VERSION ""

NS_ :

BS_:

BU_: Turbocharger OnBoardDataLogger OffBoardDiagnosticTool2 OffBoardDiagnosticTool1 FileServer ParkingBrakeController SeatControl2 FanDriveController SteeringColumnUnit CommunicationUnitRadio CommunicationUnitSatellite CommunicationUnitCellular PropulsionBatteryCharger ChassisController2 ChassisController1 EngineValveControl AuxiliaryHeater2 AuxiliaryHeater1 ClutchUnit RampControl InformationSystem1 SuspensionSystemController2 OilSensor VehicleDynamicStability ExhaustEmissionController TransmissionDisplay2 TransmissionDisplay1 ClimateControl2 WaterPumpController RearAxleSteeringController LightingOperatorControl SeatController1 IgnitionController2 IgnitionController1 TirePressureController CabController2 CabController1 PneumaticSystemController SuspensionSystemController1 HydraulicPumpController EnduranceBrakingSystem RetarderExhaustEngine2 OnBoardDiagnosticUnit HeadwayController RetarderExhaustEngine1 CabDisplay1 ManagementComputer VirtualTerminal OffVehicleGateway PowerTakeOffFront HitchControl AuxiliaryValveControl BodyController TractorTrailerBridge1 StarterSystem ElectricalSystem VehicleSecurity VehicleNavigation AerodynamicControl ElectricalChargingSystem ClimateControl1 TripRecorder InstrumentCluster SuspensionDriveAxle2 SuspensionDriveAxle1 SuspensionSteerAxle SteeringController FuelSystem CruiseControl RetarderDriveline RetarderEngine BrakesDriveAxle2 BrakesDriveAxle1 BrakesSystemController BrakesSteerAxle AxleDrive2 AxleDrive1 AxleSteering PowerTakeOff ShiftConsoleSecondary ShiftConsolePrimary Transmission2 Transmission1 Engine2 Engine1

BO_ 2632384254 VT12: 34 Vector__XXX
 SG_ VTFunctionVTtoECU M : 0|8@1+ (1,0) [0|255] "" Vector__XXX
 SG_ NumberOfAuxiliaryUnits m39 : 8|8@1+ (1,0) [0|255] "" Vector__XXX
 SG_ BootTime m199 : 8|8@1+ (1,0) [0|255] "s" Vector__XXX
 SG_ NumberOfSupportedObjects m197 : 8|8@1+ (1,0) [0|255] "" Vector__XXX
 SG_ BckgndColourUserLayoutDataMask m196 : 8|8@1+ (1,0) [0|255] "" Vector__XXX
 SG_ ObjectID_1 m9 : 8|16@1+ (1,0) [0|65535] "" Vector__XXX
 SG_ InputNumber m33 : 8|8@1+ (1,0) [0|250] "" Vector__XXX
 SG_ TerminationCause m10 : 8|8@1+ (1,0) [0|255] "" Vector__XXX
 SG_ KeyActivationCode m0 : 8|8@1+ (1,0) [0|2] "" Vector__XXX
 SG_ ButtonActivationCode m1 : 8|8@1+ (1,0) [0|2] "" Vector__XXX
 SG_ XPosition m2 : 8|16@1+ (1,0) [0|65535] "" Vector__XXX
 SG_ VTSelectInputObjectID m3 : 8|16@1+ (1,0) [0|65535] "" Vector__XXX
 SG_ VTEscObjectID m4 : 8|16@1+ (1,0) [0|65535] "" Vector__XXX
 SG_ VTChangeNumericValueObjectID m5 : 8|16@1+ (1,0) [0|65535] "" Vector__XXX
 SG_ VTChangeActiveMaskObjectID m6 : 8|16@1+ (1,0) [0|65535] "" Vector__XXX
 SG_ VTChangeSoftKeyMaskParentID m7 : 8|16@1+ (1,0) [0|65535] "" Vector__XXX
 SG_ ObjectToChangeStringID m8 : 8|16@1+ (1,0) [0|65535] "" Vector__XXX
 SG_ ErrorCodeEndOfObjectPool1 m18 : 8|1@1+ (1,0) [0|1] "" Vector__XXX
 SG_ IdentityNumber m36 : 8|21@1+ (1,0) [0|2097152] "" Vector__XXX
 SG_ InputObjectId m38 : 8|16@1+ (1,0) [0|255] "" Vector__XXX
 SG_ AuxPreferredAssignmentRespError1 m34 : 8|1@1+ (1,0) [0|1] "" Vector__XXX
 SG_ InputStatusObjectId m37 : 8|16@1+ (1,0) [0|255] "" Vector__XXX
 SG_ ObjectEscapeID m146 : 8|16@1+ (1,0) [0|65535] "" Vector__XXX
 SG_ ObjectToHideShowID m160 : 8|16@1+ (1,0) [0|65535] "" Vector__XXX
 SG_ ObjectToEnableDisableID m161 : 8|16@1+ (1,0) [0|65535] "" Vector__XXX
 SG_ SelectInputObjectID m162 : 8|16@1+ (1,0) [0|65535] "" Vector__XXX
 SG_ ErrorCodeControlAudioDevice1 m163 : 8|1@1+ (1,0) [0|1] "" Vector__XXX
 SG_ ErrorCodeAudioVolume1 m164 : 8|1@1+ (1,0) [0|1] "" Vector__XXX
 SG_ ChangeChildLocationParentOb_0001 m165 : 8|16@1+ (1,0) [0|65535] "" Vector__XXX
 SG_ ObjectToSizeID m166 : 8|16@1+ (1,0) [0|65535] "" Vector__XXX
 SG_ ObjectToChangeColourID m167 : 8|16@1+ (1,0) [0|65535] "" Vector__XXX
 SG_ ObjectToChangeNumValueID m168 : 8|16@1+ (1,0) [0|65535] "" Vector__XXX
 SG_ ObjectToChangeEndPointID m169 : 8|16@1+ (1,0) [0|65535] "" Vector__XXX
 SG_ ObjectToChangeFontID m170 : 8|16@1+ (1,0) [0|65535] "" Vector__XXX
 SG_ ObjectToChangeLineAttributeID m171 : 8|16@1+ (1,0) [0|65535] "" Vector__XXX
 SG_ ObjectToChangeFillAttributesID m172 : 8|16@1+ (1,0) [0|65535] "" Vector__XXX
 SG_ ActiveMaskObjectID m173 : 8|16@1+ (1,0) [0|0] "" Vector__XXX
 SG_ DataOrAlarmMaskObjectID m174 : 8|16@1+ (1,0) [0|65535] "" Vector__XXX
 SG_ ObjectToChangeAttributeID m175 : 8|16@1+ (1,0) [0|65535] "" Vector__XXX
 SG_ AlarmMaskObjectID m176 : 8|16@1+ (1,0) [0|65535] "" Vector__XXX
 SG_ ListInputObjectID m177 : 8|16@1+ (1,0) [0|65535] "" Vector__XXX
 SG_ ErrorCodeDeleteObjectPool1 m178 : 8|1@1+ (1,0) [0|1] "" Vector__XXX
 SG_ ChangeChildPositionParentOb_0001 m180 : 8|16@1+ (1,0) [0|65535] "" Vector__XXX
 SG_ ErrorCodeSetObjectLabel1 m181 : 8|1@1+ (1,0) [0|1] "" Vector__XXX
 SG_ PolygonObjectToChangeID m182 : 8|16@1+ (1,0) [0|65535] "" Vector__XXX
 SG_ PolygonObjectToScaleID m183 : 8|16@1+ (1,0) [0|65535] "" Vector__XXX
 SG_ GraphicsContextObjectID m184 : 8|16@1+ (1,0) [0|65535] "" Vector__XXX
 SG_ ObjectToGetAttributeID m185 : 8|16@1+ (1,0) [0|65535] "" Vector__XXX
 SG_ ColourMapObjectID m186 : 8|16@1+ (1,0) [0|65535] "" Vector__XXX
 SG_ LockUnlockCommand m189 : 8|8@1+ (1,0) [0|1] "" Vector__XXX
 SG_ MacroObjecID m190 : 8|8@1+ (1,0) [0|255] "" Vector__XXX
 SG_ VersionNumberISO11783Part6 m192 : 8|8@1+ (1,0) [0|255] "" Vector__XXX
 SG_ CodePlane m193 : 8|8@1+ (1,0) [0|16] "" Vector__XXX
 SG_ NavigationSoftKeys m194 : 8|8@1+ (1,0) [0|254] "" Vector__XXX
 SG_ NrOfVersionStrings m224 : 8|8@1+ (1,0) [0|255] "" Vector__XXX
 SG_ ParentIDOfFaultyObject m240 : 8|16@1+ (1,0) [0|65535] "" Vector__XXX
 SG_ SourceAdressOfActiveWSM m254 : 8|8@1+ (1,0) [0|255] "" Vector__XXX
 SG_ ErrorCodeEndOfObjectPool2 m18 : 9|1@1+ (1,0) [0|1] "" Vector__XXX
 SG_ AuxPreferredAssignmentRespError2 m34 : 9|1@1+ (1,0) [0|1] "" Vector__XXX
 SG_ ErrorCodeSetObjectLabel2 m181 : 9|1@1+ (1,0) [0|1] "" Vector__XXX
 SG_ AuxPreferredAssignmentRespError3 m34 : 10|1@1+ (1,0) [0|1] "" Vector__XXX
 SG_ ErrorCodeSetObjectLabel3 m181 : 10|1@1+ (1,0) [0|1] "" Vector__XXX
 SG_ AuxPreferredAssignmentRespError4 m34 : 11|1@1+ (1,0) [0|1] "" Vector__XXX
 SG_ ErrorCodeSetObjectLabel4 m181 : 11|1@1+ (1,0) [0|1] "" Vector__XXX
 SG_ AuxPreferredAssignmentRespError5 m34 : 12|1@1+ (1,0) [0|1] "" Vector__XXX
 SG_ ErrorCodeEndOfObjectPool3 m18 : 12|1@1+ (1,0) [0|1] "" Vector__XXX
 SG_ ErrorCodeControlAudioDevice2 m163 : 12|1@1+ (1,0) [0|1] "" Vector__XXX
 SG_ ErrorCodeAudioVolume2 m164 : 12|1@1+ (1,0) [0|1] "" Vector__XXX
 SG_ ErrorCodeDeleteObjectPool2 m178 : 12|1@1+ (1,0) [0|1] "" Vector__XXX
 SG_ ErrorCodeSetObjectLabel5 m181 : 12|1@1+ (1,0) [0|1] "" Vector__XXX
 SG_ ErrorCodeSetObjectLabel6 m181 : 13|1@1+ (1,0) [0|1] "" Vector__XXX
 SG_ BckgndColourUserLayoutSoftkeyMas m196 : 16|8@1+ (1,0) [0|255] "" Vector__XXX
 SG_ AnalogValue m33 : 16|16@1+ (1,0) [0|65535] "" Vector__XXX
 SG_ AuxFunctObjOfFaultyAssignment m34 : 16|16@1- (1,0) [0|65535] "" Vector__XXX
 SG_ KeyObjectID m0 : 16|16@1+ (1,0) [0|65535] "" Vector__XXX
 SG_ ButtonObjectID m1 : 16|16@1+ (1,0) [0|65535] "" Vector__XXX
 SG_ ParentObjectIDOfFaultyObject m18 : 16|16@1+ (1,0) [0|65535] "" Vector__XXX
 SG_ ErrorCodeLockUnlockMask1 m189 : 16|1@1+ (1,0) [0|1] "" Vector__XXX
 SG_ ErrorCodeExecuteMacro1 m190 : 16|1@1+ (1,0) [0|1] "" Vector__XXX
 SG_ MemoryStatus m192 : 16|8@1+ (1,0) [0|1] "" Vector__XXX
 SG_ FirstWideChar m193 : 16|16@1+ (1,0) [0|65535] "" Vector__XXX
 SG_ SupportedGraphicMode m199 : 16|8@1+ (1,0) [0|2] "" Vector__XXX
 SG_ VersionLables m224 : 16|56@1+ (1,0) [0|0] "" Vector__XXX
 SG_ VisibleDataOrAlarmMaskObjectID m254 : 16|16@1+ (1,0) [0|65535] "" Vector__XXX
 SG_ ExtendedVersionLables m211 : 16|256@1+ (1,0) [0|7.20575940379279E+016] "" Vector__XXX
 SG_ NameOfAuxiliaryUnit1 m39 : 16|64@1+ (1,0) [0|0] "" Vector__XXX
 SG_ ErrorCodeLockUnlockMask2 m189 : 17|1@1+ (1,0) [0|1] "" Vector__XXX
 SG_ ErrorCodeExecuteMacro2 m190 : 17|1@1+ (1,0) [0|1] "" Vector__XXX
 SG_ ErrorCodeLockUnlockMask3 m189 : 18|1@1+ (1,0) [0|1] "" Vector__XXX
 SG_ ErrorCodeExecuteMacro3 m190 : 18|1@1+ (1,0) [0|1] "" Vector__XXX
 SG_ ErrorCodeLockUnlockMask4 m189 : 19|1@1+ (1,0) [0|1] "" Vector__XXX
 SG_ ErrorCodeLockUnlockMask5 m189 : 20|1@1+ (1,0) [0|1] "" Vector__XXX
 SG_ ErrorCodeLockUnlockMask6 m189 : 21|1@1+ (1,0) [0|1] "" Vector__XXX
 SG_ ErrorCodeLockUnlockMask7 m189 : 22|1@1+ (1,0) [0|1] "" Vector__XXX
 SG_ ErrorCodeLockUnlockMask8 m189 : 23|1@1+ (1,0) [0|1] "" Vector__XXX
 SG_ Status_1 m9 : 24|8@1+ (1,0) [0|1] "" Vector__XXX
 SG_ YPosition m2 : 24|16@1+ (1,0) [0|65535] "" Vector__XXX
 SG_ VTSelectInputObjectStatus m3 : 24|8@1+ (1,0) [0|1] "" Vector__XXX
 SG_ ErrorCodeVTEsc1 m4 : 24|1@1+ (1,0) [0|1] "" Vector__XXX
 SG_ VTChangeSoftKeyMaskObjectID m7 : 24|16@1+ (1,0) [0|65535] "" Vector__XXX
 SG_ EnteredStringValue m8 : 24|8@1+ (1,0) [0|255] "" Vector__XXX
 SG_ Value1 m38 : 24|16@1+ (1,0) [0|65535] "" Vector__XXX
 SG_ AuxInputEnable m37 : 24|8@1+ (1,0) [0|1] "" Vector__XXX
 SG_ ErrorCodeEscapeObj1 m146 : 24|1@1+ (1,0) [0|1] "" Vector__XXX
 SG_ ObjectShowStatus m160 : 24|8@1+ (1,0) [0|1] "" Vector__XXX
 SG_ ObjectEnableStatus m161 : 24|8@1+ (1,0) [0|1] "" Vector__XXX
 SG_ ObjectSelectStatus m162 : 24|8@1+ (1,0) [0|2] "" Vector__XXX
 SG_ ChangeChildLocationObjectID m165 : 24|16@1+ (1,0) [0|65535] "" Vector__XXX
 SG_ ErrorCodeObjToSize1 m166 : 24|1@1+ (1,0) [0|1] "" Vector__XXX
 SG_ NewBackgroundColour m167 : 24|8@1+ (1,0) [0|255] "" Vector__XXX
 SG_ ErrorCodeChangeNumValue1 m168 : 24|1@1+ (1,0) [0|1] "" Vector__XXX
 SG_ ErrorCodeChangeEditPoint1 m169 : 24|1@1+ (1,0) [0|1] "" Vector__XXX
 SG_ ErrorCodeChangeFont1 m170 : 24|1@1+ (1,0) [0|1] "" Vector__XXX
 SG_ ErrorCodeChangeLineAttribute1 m171 : 24|1@1+ (1,0) [0|1] "" Vector__XXX
 SG_ ErrorCodeChangeFillAttributes1 m172 : 24|1@1+ (1,0) [0|1] "" Vector__XXX
 SG_ ErrorCodeChangeActiveMask1 m173 : 24|1@1+ (1,0) [0|1] "" Vector__XXX
 SG_ SoftKeyMaskObjectID m174 : 24|16@1+ (1,0) [0|65535] "" Vector__XXX
 SG_ AttributeToChangeID m175 : 24|8@1+ (1,0) [0|65535] "" Vector__XXX
 SG_ NewPriority m176 : 24|8@1+ (1,0) [0|255] "" Vector__XXX
 SG_ ListIndex m177 : 24|8@1+ (1,0) [0|255] "" Vector__XXX
 SG_ ChangeStringValueObjectID m179 : 24|16@1+ (1,0) [0|65535] "" Vector__XXX
 SG_ ChangeChildPositionObjectID m180 : 24|16@1+ (1,0) [0|65535] "" Vector__XXX
 SG_ ErrorCodeChangePoygonPoint1 m182 : 24|1@1+ (1,0) [0|1] "" Vector__XXX
 SG_ NewWidthAttribute m183 : 24|16@1+ (1,0) [0|65535] "" Vector__XXX
 SG_ SubCommandID m184 : 24|8@1+ (1,0) [0|0] "" Vector__XXX
 SG_ AttributeID m185 : 24|8@1+ (1,0) [0|16777200] "" Vector__XXX
 SG_ ErrorCodeSelectColourMap1 m186 : 24|1@1+ (1,0) [0|1] "" Vector__XXX
 SG_ Hardware1 m199 : 24|1@1+ (1,0) [0|1] "" Vector__XXX
 SG_ ObjectIDOfFaultyObject m240 : 24|16@1+ (1,0) [0|65535] "" Vector__XXX
 SG_ ErrorCodeExecuteOpCode1 m11 : 24|1@1+ (1,0) [0|1] "" Vector__XXX
 SG_ ErrorCodeObjToSize2 m166 : 25|1@1+ (1,0) [0|1] "" Vector__XXX
 SG_ ErrorCodeChangeNumValue2 m168 : 25|1@1+ (1,0) [0|1] "" Vector__XXX
 SG_ ErrorCodeChangeEditPoint2 m169 : 25|1@1+ (1,0) [0|1] "" Vector__XXX
 SG_ ErrorCodeChangeFont2 m170 : 25|1@1+ (1,0) [0|1] "" Vector__XXX
 SG_ ErrorCodeChangeLineAttribute2 m171 : 25|1@1+ (1,0) [0|1] "" Vector__XXX
 SG_ ErrorCodeChangeFillAttributes2 m172 : 25|1@1+ (1,0) [0|1] "" Vector__XXX
 SG_ ErrorCodeChangeActiveMask2 m173 : 25|1@1+ (1,0) [0|1] "" Vector__XXX
 SG_ ErrorCodeChangePoygonPoint2 m182 : 25|1@1+ (1,0) [0|1] "" Vector__XXX
 SG_ ErrorCodeSelectColourMap2 m186 : 25|1@1+ (1,0) [0|1] "" Vector__XXX
 SG_ Hardware2 m199 : 25|1@1+ (1,0) [0|1] "" Vector__XXX
 SG_ ErrorCodeExecuteOpCode2 m11 : 25|1@1+ (1,0) [0|1] "" Vector__XXX
 SG_ ErrorCodeMissingObjects m6 : 26|1@1+ (1,0) [0|1] "" Vector__XXX
 SG_ ErrorCodeObjToSize3 m166 : 26|1@1+ (1,0) [0|1] "" Vector__XXX
 SG_ ErrorCodeChangeFont3 m170 : 26|1@1+ (1,0) [0|1] "" Vector__XXX
 SG_ ErrorCodeChangeLineAttribute3 m171 : 26|1@1+ (1,0) [0|1] "" Vector__XXX
 SG_ ErrorCodeChangeFillAttributes3 m172 : 26|1@1+ (1,0) [0|1] "" Vector__XXX
 SG_ ErrorCodeChangeActiveMask3 m173 : 26|1@1+ (1,0) [0|1] "" Vector__XXX
 SG_ ErrorCodeChangePoygonPoint3 m182 : 26|1@1+ (1,0) [0|1] "" Vector__XXX
 SG_ Hardware3 m199 : 26|1@1+ (1,0) [0|1] "" Vector__XXX
 SG_ ErrorCodeExecuteOpCode3 m11 : 26|1@1+ (1,0) [0|1] "" Vector__XXX
 SG_ ErrorCodeChangeNumValue3 m168 : 26|1@1+ (1,0) [0|1] "" Vector__XXX
 SG_ ErrorCodeMaskOrChildObjectError m6 : 27|1@1+ (1,0) [0|1] "" Vector__XXX
 SG_ ErrorCodeChangeFont4 m170 : 27|1@1+ (1,0) [0|1] "" Vector__XXX
 SG_ ErrorCodeChangeFillAttributes4 m172 : 27|1@1+ (1,0) [0|1] "" Vector__XXX
 SG_ ErrorCodeChangeActiveMask4 m173 : 27|1@1+ (1,0) [0|1] "" Vector__XXX
 SG_ Hardware4 m199 : 27|1@1+ (1,0) [0|1] "" Vector__XXX
 SG_ ErrorCodeExecuteOpCode4 m11 : 27|1@1+ (1,0) [0|1] "" Vector__XXX
 SG_ ErrorCodeChangeNumValue4 m168 : 28|1@1+ (1,0) [0|1] "" Vector__XXX
 SG_ ErrorCodeVTEsc2 m4 : 28|1@1+ (1,0) [0|1] "" Vector__XXX
 SG_ ErrorCodeAnyOtherError m6 : 28|1@1+ (1,0) [0|1] "" Vector__XXX
 SG_ ErrorCodeEscapeObj2 m146 : 28|1@1+ (1,0) [0|1] "" Vector__XXX
 SG_ ErrorCodeObjToSize4 m166 : 28|1@1+ (1,0) [0|1] "" Vector__XXX
 SG_ ErrorCodeExecuteOpCode5 m11 : 28|1@1+ (1,0) [0|1] "" Vector__XXX
 SG_ ErrorCodeChangeEditPoint3 m169 : 28|1@1+ (1,0) [0|1] "" Vector__XXX
 SG_ ErrorCodeChangeFont5 m170 : 28|1@1+ (1,0) [0|1] "" Vector__XXX
 SG_ ErrorCodeChangeLineAttribute4 m171 : 28|1@1+ (1,0) [0|1] "" Vector__XXX
 SG_ ErrorCodeChangeFillAttributes5 m172 : 28|1@1+ (1,0) [0|1] "" Vector__XXX
 SG_ ErrorCodeChangeActiveMask5 m173 : 28|1@1+ (1,0) [0|1] "" Vector__XXX
 SG_ Hardware5 m199 : 28|1@1+ (1,0) [0|1] "" Vector__XXX
 SG_ ErrorCodePoolDeleted m6 : 29|1@1+ (1,0) [0|1] "" Vector__XXX
 SG_ ErrorCodeExecuteOpCode6 m11 : 29|1@1+ (1,0) [0|1] "" Vector__XXX
 SG_ ManufacturerCode m36 : 29|11@1+ (1,0) [0|2047] "" Vector__XXX
 SG_ ErrorCodeChangeFont6 m170 : 29|1@1+ (1,0) [0|1] "" Vector__XXX
 SG_ Hardware6 m199 : 29|1@1+ (1,0) [0|1] "" Vector__XXX
 SG_ ErrorCodeExecuteOpCode7 m11 : 30|1@1+ (1,0) [0|1] "" Vector__XXX
 SG_ ObjectID_2 m9 : 32|16@1+ (1,0) [0|65535] "" Vector__XXX
 SG_ NumTransitionsDisabledToEnabled m33 : 32|16@1+ (1,0) [0|65535] "" Vector__XXX
 SG_ KeyObjectParentID m0 : 32|16@1+ (1,0) [0|65535] "" Vector__XXX
 SG_ ButtonObjectParentID m1 : 32|16@1+ (1,0) [0|65535] "" Vector__XXX
 SG_ VTSelectInputObjectIsEdited m3 : 32|1@1+ (1,0) [0|1] "" Vector__XXX
 SG_ VTChangeNumericValueValue m5 : 32|32@1+ (1,0) [0|4294967295] "" Vector__XXX
 SG_ VTChangeActiveMaskErrorID m6 : 32|16@1+ (1,0) [0|65535] "" Vector__XXX
 SG_ ObjectIdOfFaultyObject m18 : 32|16@1+ (1,0) [0|65535] "" Vector__XXX
 SG_ ErrorCodeHideShowObj1 m160 : 32|1@1+ (1,0) [0|1] "" Vector__XXX
 SG_ ErrorCodeSelectObject1 m162 : 32|1@1+ (1,0) [0|1] "" Vector__XXX
 SG_ ErrorCodeChangeColour1 m167 : 32|1@1+ (1,0) [0|1] "" Vector__XXX
 SG_ ValueOfTheObject m168 : 32|32@1+ (1,0) [0|2704] "" Vector__XXX
 SG_ ErrorCodeChangeAttribute1 m175 : 32|1@1+ (1,0) [0|1] "" Vector__XXX
 SG_ ErrorCodeChangePriority1 m176 : 32|1@1+ (1,0) [0|1] "" Vector__XXX
 SG_ NewObjectID m177 : 32|16@1+ (1,0) [0|65535] "" Vector__XXX
 SG_ ErrorCodeGraphicsContextCmd1 m184 : 32|1@1+ (1,0) [0|1] "" Vector__XXX
 SG_ LastWideChar m193 : 32|16@1+ (1,0) [0|65535] "" Vector__XXX
 SG_ XDotsForSoftKeyDescriptor m194 : 32|8@1+ (1,0) [0|255] "" Vector__XXX
 SG_ NrOfXPixelsInDataAreaMask m199 : 32|16@1+ (1,0) [0|65535] "" Vector__XXX
 SG_ VisibleSoftKeyMaskObjectID m254 : 32|16@1+ (1,0) [0|65535] "" Vector__XXX
 SG_ ErrorCodeHideShowObj2 m160 : 33|1@1+ (1,0) [0|1] "" Vector__XXX
 SG_ ErrorCodeEnableDisableObj1 m161 : 33|1@1+ (1,0) [0|1] "" Vector__XXX
 SG_ ErrorCodeSelectObject2 m162 : 33|1@1+ (1,0) [0|1] "" Vector__XXX
 SG_ ErrorCodeChangeColour2 m167 : 33|1@1+ (1,0) [0|1] "" Vector__XXX
 SG_ ErrorCodeChangeAttribute2 m175 : 33|1@1+ (1,0) [0|1] "" Vector__XXX
 SG_ ErrorCodeChangePriority2 m176 : 33|1@1+ (1,0) [0|1] "" Vector__XXX
 SG_ ErrorCodeGraphicsContextCmd2 m184 : 33|1@1+ (1,0) [0|1] "" Vector__XXX
 SG_ ErrorCodeEnableDisableObj2 m161 : 34|1@1+ (1,0) [0|1] "" Vector__XXX
 SG_ ErrorCodeSelectObject3 m162 : 34|1@1+ (1,0) [0|1] "" Vector__XXX
 SG_ ErrorCodeChangeAttribute3 m175 : 34|1@1+ (1,0) [0|1] "" Vector__XXX
 SG_ ErrorCodeGraphicsContextCmd3 m184 : 34|1@1+ (1,0) [0|1] "" Vector__XXX
 SG_ ErrorCodeHideShowObj3 m160 : 35|1@1+ (1,0) [0|1] "" Vector__XXX
 SG_ ErrorCodeEnableDisableObj3 m161 : 35|1@1+ (1,0) [0|1] "" Vector__XXX
 SG_ ErrorCodeSelectObject4 m162 : 35|1@1+ (1,0) [0|1] "" Vector__XXX
 SG_ ErrorCodeGraphicsContextCmd4 m184 : 35|1@1+ (1,0) [0|1] "" Vector__XXX
 SG_ ErrorCodeEnableDisableObj4 m161 : 36|1@1+ (1,0) [0|1] "" Vector__XXX
 SG_ ErrorCodeSelectObject5 m162 : 36|1@1+ (1,0) [0|1] "" Vector__XXX
 SG_ ErrorCodeChangeColour3 m167 : 36|1@1+ (1,0) [0|1] "" Vector__XXX
 SG_ ErrorCodeChangeAttribute4 m175 : 35|1@1+ (1,0) [0|1] "" Vector__XXX
 SG_ ErrorCodeChangePriority3 m176 : 36|1@1+ (1,0) [0|1] "" Vector__XXX
 SG_ ErrorCodeGraphicsContextCmd5 m184 : 36|1@1+ (1,0) [0|1] "" Vector__XXX
 SG_ ErrorCodeSelectObject6 m162 : 37|1@1+ (1,0) [0|1] "" Vector__XXX
 SG_ ErrorCodeVTChangeSoftKeyMask1 m7 : 40|1@1+ (1,0) [0|1] "" Vector__XXX
 SG_ TouchState m2 : 40|8@1+ (1,0) [0|255] "" Vector__XXX
 SG_ ECUInstance m36 : 40|3@1+ (1,0) [0|7] "" Vector__XXX
 SG_ Value2 m38 : 40|16@1+ (1,0) [0|65535] "" Vector__XXX
 SG_ ErrorCodeChangeChildLocation1 m165 : 40|1@1+ (1,0) [0|1] "" Vector__XXX
 SG_ ErrorCodeChangeSoftKeyMask1 m174 : 40|1@1+ (1,0) [0|1] "" Vector__XXX
 SG_ ErrorCodeChangePosInvalidParent m180 : 40|1@1+ (1,0) [0|1] "" Vector__XXX
 SG_ NewHeigthAttribute m183 : 40|16@1+ (1,0) [0|0] "" Vector__XXX
 SG_ YDotsForSoftKeyDescriptor m194 : 40|8@1+ (1,0) [0|255] "" Vector__XXX
 SG_ FontSize_8x8 m195 : 40|1@1+ (1,0) [0|1] "" Vector__XXX
 SG_ AcknowledgmentStoreVersion m208 : 40|4@1+ (1,0) [0|8] "" Vector__XXX
 SG_ AcknowledgmentLoadVersion m209 : 40|4@1+ (1,0) [0|8] "" Vector__XXX
 SG_ AcknowledgmentDeleteVersion m210 : 40|4@1+ (1,0) [0|8] "" Vector__XXX
 SG_ ErrorCodeVtObjPoolError1 m240 : 40|1@1+ (1,0) [0|1] "" Vector__XXX
 SG_ ErrorCodeVTChangeSoftKeyMask2 m7 : 41|1@1+ (1,0) [0|1] "" Vector__XXX
 SG_ ErrorCodeChangeChildLocation2 m165 : 41|1@1+ (1,0) [0|1] "" Vector__XXX
 SG_ ErrorCodeChangeSoftKeyMask2 m174 : 41|1@1+ (1,0) [0|1] "" Vector__XXX
 SG_ ErrorCodeChangeStrObjectID m179 : 41|1@1+ (1,0) [0|1] "" Vector__XXX
 SG_ ErrorCodeChangePosInvalidObject m180 : 41|1@1+ (1,0) [0|1] "" Vector__XXX
 SG_ FontSize_8x12 m195 : 41|1@1+ (1,0) [0|1] "" Vector__XXX
 SG_ ErrorCodeVtObjPoolError2 m240 : 41|1@1+ (1,0) [0|1] "" Vector__XXX
 SG_ ErrorCodeVTChangeSoftKeyMask3 m7 : 42|1@1+ (1,0) [0|1] "" Vector__XXX
 SG_ ErrorCodeChangeSoftKeyMask3 m174 : 42|1@1+ (1,0) [0|1] "" Vector__XXX
 SG_ ErrorCodeChangeStrTooLong m179 : 42|1@1+ (1,0) [0|1] "" Vector__XXX
 SG_ FontSize_12x16 m195 : 42|1@1+ (1,0) [0|1] "" Vector__XXX
 SG_ ErrorCodeVtObjPoolError3 m240 : 42|1@1+ (1,0) [0|1] "" Vector__XXX
 SG_ ErrorCodeVTChangeSoftKeyMask4 m7 : 43|1@1+ (1,0) [0|1] "" Vector__XXX
 SG_ FunctionInstance m36 : 43|5@1+ (1,0) [0|31] "" Vector__XXX
 SG_ ErrorCodeChangeSoftKeyMask4 m174 : 43|1@1+ (1,0) [0|1] "" Vector__XXX
 SG_ ErrorCodeChangeStrError m179 : 43|1@1+ (1,0) [0|1] "" Vector__XXX
 SG_ FontSize_16x16 m195 : 43|1@1+ (1,0) [0|1] "" Vector__XXX
 SG_ ErrorCodeVtObjPoolError4 m240 : 43|1@1+ (1,0) [0|1] "" Vector__XXX
 SG_ ErrorCodeChangeStrValueInUse m179 : 44|1@1+ (1,0) [0|1] "" Vector__XXX
 SG_ ErrorCodeVTChangeSoftKeyMask5 m7 : 44|1@1+ (1,0) [0|1] "" Vector__XXX
 SG_ ErrorCodeChangeChildLocation5 m165 : 44|1@1+ (1,0) [0|1] "" Vector__XXX
 SG_ ErrorCodeChangeSoftKeyMask5 m174 : 44|1@1+ (1,0) [0|1] "" Vector__XXX
 SG_ ErrorCodeChangePosInvalidError m180 : 44|1@1+ (1,0) [0|1] "" Vector__XXX
 SG_ FontSize_16x24 m195 : 44|1@1+ (1,0) [0|1] "" Vector__XXX
 SG_ FontSize_24x32 m195 : 45|1@1+ (1,0) [0|1] "" Vector__XXX
 SG_ FontSize_32x32 m195 : 46|1@1+ (1,0) [0|1] "" Vector__XXX
 SG_ Status_2 m9 : 48|8@1+ (1,0) [0|1] "" Vector__XXX
 SG_ BooleanValue m33 : 48|8@1+ (1,0) [0|2] "" Vector__XXX
 SG_ SoftKeyCode m0 : 48|8@1+ (1,0) [0|255] "" Vector__XXX
 SG_ ButtonKeyCode m1 : 48|8@1+ (1,0) [0|255] "" Vector__XXX
 SG_ VTChangeActiveMaskParentID m6 : 48|16@1+ (1,0) [0|65535] "" Vector__XXX
 SG_ ErrorCodeObjectPool1 m18 : 48|1@1+ (1,0) [0|1] "" Vector__XXX
 SG_ Function m36 : 48|8@1+ (1,0) [0|255] "" Vector__XXX
 SG_ ErrorCodeChangeListItem1 m177 : 48|1@1+ (1,0) [0|1] "" Vector__XXX
 SG_ ErrorCodeGetSupportedWideChars1 m193 : 48|1@1+ (1,0) [0|1] "" Vector__XXX
 SG_ NumberOfPossibleVirtualSoftKeys m194 : 48|8@1+ (1,0) [0|255] "" Vector__XXX
 SG_ FontSize_32x48 m195 : 48|1@1+ (1,0) [0|1] "" Vector__XXX
 SG_ NrOfYPixelsInDataAreaMask m199 : 48|16@1+ (1,0) [0|65535] "" Vector__XXX
 SG_ VTBusyCode1 m254 : 48|1@1+ (1,0) [0|1] "" Vector__XXX
 SG_ ErrorCodeObjectPool2 m18 : 49|1@1+ (1,0) [0|1] "" Vector__XXX
 SG_ ErrorCodeChangeListItem2 m177 : 49|1@1+ (1,0) [0|1] "" Vector__XXX
 SG_ FontSize_48x64 m195 : 49|1@1+ (1,0) [0|1] "" Vector__XXX
 SG_ VTBusyCode2 m254 : 49|1@1+ (1,0) [0|1] "" Vector__XXX
 SG_ ErrorCodeObjectPool3 m18 : 50|1@1+ (1,0) [0|1] "" Vector__XXX
 SG_ ErrorCodeChangeListItem3 m177 : 50|1@1+ (1,0) [0|1] "" Vector__XXX
 SG_ FontSize_64x64 m195 : 50|1@1+ (1,0) [0|1] "" Vector__XXX
 SG_ VTBusyCode3 m254 : 50|1@1+ (1,0) [0|1] "" Vector__XXX
 SG_ ErrorCodeObjectPool4 m18 : 51|1@1+ (1,0) [0|1] "" Vector__XXX
 SG_ FontSize_64x96 m195 : 51|1@1+ (1,0) [0|1] "" Vector__XXX
 SG_ VTBusyCode4 m254 : 51|1@1+ (1,0) [0|1] "" Vector__XXX
 SG_ ErrorCodeChangeListItem4 m177 : 51|1@1+ (1,0) [0|1] "" Vector__XXX
 SG_ ErrorCodeChangeListItem5 m177 : 52|1@1+ (1,0) [0|1] "" Vector__XXX
 SG_ ErrorCodeGetSupportedWideChars2 m193 : 52|1@1+ (1,0) [0|1] "" Vector__XXX
 SG_ FontSize_96x128 m195 : 52|1@1+ (1,0) [0|1] "" Vector__XXX
 SG_ VTBusyCode5 m254 : 52|1@1+ (1,0) [0|1] "" Vector__XXX
 SG_ FontSize_128x128 m195 : 53|1@1+ (1,0) [0|1] "" Vector__XXX
 SG_ VTBusyCode7 m254 : 54|1@1+ (1,0) [0|1] "" Vector__XXX
 SG_ FontSize_128x192 m195 : 54|1@1+ (1,0) [0|1] "" Vector__XXX
 SG_ VTBusyCode8 m254 : 55|1@1+ (1,0) [0|1] "" Vector__XXX
 SG_ OperatingState1 m38 : 56|1@1+ (1,0) [0|1] "" Vector__XXX
 SG_ ErrorCodeChangePolygonScale1 m183 : 56|1@1+ (1,0) [0|1] "" Vector__XXX
 SG_ NumberOfRanges m193 : 56|8@1+ (1,0) [0|255] "" Vector__XXX
 SG_ NumberOfPhysicalSoftKeys m194 : 56|8@1+ (1,0) [0|255] "" Vector__XXX
 SG_ FontType_BoldText m195 : 56|1@1+ (1,0) [0|1] "" Vector__XXX
 SG_ VTFunctionCode m254 : 56|8@1+ (1,0) [0|255] "" Vector__XXX
 SG_ OperatingState2 m38 : 57|1@1+ (1,0) [0|1] "" Vector__XXX
 SG_ DeviceClass m36 : 57|7@1+ (1,0) [0|127] "" Vector__XXX
 SG_ FontType_CrossedOutText m195 : 57|1@1+ (1,0) [0|1] "" Vector__XXX
 SG_ FontType_UnderlinedText m195 : 58|1@1+ (1,0) [0|1] "" Vector__XXX
 SG_ FontType_ItalicsText m195 : 59|1@1+ (1,0) [0|1] "" Vector__XXX
 SG_ ErrorCodeChangePolygonScale5 m183 : 60|1@1+ (1,0) [0|1] "" Vector__XXX
 SG_ FontType_InvertedText m195 : 60|1@1+ (1,0) [0|1] "" Vector__XXX
 SG_ FontType_FlashInverted m195 : 61|1@1+ (1,0) [0|1] "" Vector__XXX
 SG_ FontType_FlashHidden m195 : 62|1@1+ (1,0) [0|1] "" Vector__XXX
 SG_ FontType_ProportionalFont m195 : 63|1@1+ (1,0) [0|1] "" Vector__XXX
 SG_ IndustryGroup m36 : 64|3@1+ (1,0) [0|7] "" Vector__XXX
 SG_ DeviceClassInstance m36 : 67|4@1+ (1,0) [0|15] "" Vector__XXX
 SG_ SelfConfigurableAddress m36 : 71|1@1+ (1,0) [0|1] "" Vector__XXX
 SG_ AuxiliaryFunctionType m36 : 72|4@1+ (1,0) [0|15] "" Vector__XXX
 SG_ ErrorCodeChangeAttribute5 m175 : 76|1@1+ (1,0) [0|1] "" Vector__XXX
 SG_ StoreAsPreferredAssignment m36 : 79|1@1+ (1,0) [0|1] "" Vector__XXX
 SG_ AuxiliaryInputObjectID m36 : 80|16@1+ (1,0) [0|65535] "" Vector__XXX
 SG_ NumberOfDifferentSetsOfUnit1 m39 : 80|8@1+ (1,0) [0|255] "" Vector__XXX
 SG_ NumberOfInstancesOfSet1 m39 : 88|8@1+ (1,0) [0|255] "" Vector__XXX
 SG_ AuxiliaryFunctionObjectID m36 : 96|16@1+ (1,0) [0|65535] "" Vector__XXX
 SG_ FunctionAttributeOfSet1 m39 : 96|8@1+ (1,0) [0|255] "" Vector__XXX
 SG_ AssignedAttribute1OfSet1 m39 : 104|1@1+ (1,0) [0|1] "" Vector__XXX
 SG_ AssignedAttribute2OfSet1 m39 : 105|1@1+ (1,0) [0|1] "" Vector__XXX

BO_ 2365458942 TFR: 8 Vector__XXX
 SG_ SpeedInfo_EngineSpeed : 0|1@1+ (1,0) [0|1] "" Vector__XXX
 SG_ SpeedInfo_GroundBasedSpeed : 1|1@1+ (1,0) [0|1] "" Vector__XXX
 SG_ SpeedInfo_WheelBasedSpeed : 2|1@1+ (1,0) [0|1] "" Vector__XXX
 SG_ PowerMgt_MaintainPower : 3|1@1+ (1,0) [0|1] "" Vector__XXX
 SG_ PowerMgt_MaxTimeTractorPower : 4|1@1+ (1,0) [0|1] "" Vector__XXX
 SG_ PowerMgt_KeySwitch : 5|1@1+ (1,0) [0|1] "" Vector__XXX
 SG_ TractorClass : 6|2@1+ (1,0) [0|3] "" Vector__XXX
 SG_ LanguageCmdStorageInTractorECU : 10|1@1+ (1,0) [0|1] "" Vector__XXX
 SG_ Lighting_MinimalSet : 11|1@1+ (1,0) [0|1] "" Vector__XXX
 SG_ PTOInfo_RearShaftEngagement : 12|1@1+ (1,0) [0|0] "" Vector__XXX
 SG_ PTOInfo_RearShaftSpeed : 13|1@1+ (1,0) [0|1] "" Vector__XXX
 SG_ HitchInfo_RearInWork : 14|1@1+ (1,0) [0|1] "" Vector__XXX
 SG_ HitchInfo_RearPosition : 15|1@1+ (1,0) [0|1] "" Vector__XXX
 SG_ EstimatedOrMeasuredAuxValveState : 16|1@1+ (1,0) [0|1] "" Vector__XXX
 SG_ Light_FullImplLightingMessageSet : 17|1@1+ (1,0) [0|1] "" Vector__XXX
 SG_ AddHitchParameter_RearDraft : 18|1@1+ (1,0) [0|1] "" Vector__XXX
 SG_ SpeedAndDist_WheelBasedDirection : 19|1@1+ (1,0) [0|1] "" Vector__XXX
 SG_ SpeedAndDist_WheelBasedDistance : 20|1@1+ (1,0) [0|1] "" Vector__XXX
 SG_ SpeedAndDist_GndBasedDirection : 21|1@1+ (1,0) [0|1] "" Vector__XXX
 SG_ SpeedAndDist_GndBasedDistance : 22|1@1+ (1,0) [0|1] "" Vector__XXX
 SG_ TimeDate : 23|1@1+ (1,0) [0|1] "" Vector__XXX
 SG_ LimitStatusReporting : 27|1@1+ (1,0) [0|0] "" Vector__XXX
 SG_ AuxiliaryValveCmd : 28|1@1+ (1,0) [0|1] "" Vector__XXX
 SG_ PTOCmd_RearPTOEngagementCmd : 29|1@1+ (1,0) [0|1] "" Vector__XXX
 SG_ PTOCmd_RearPTOSpeedCmd : 30|1@1+ (1,0) [0|1] "" Vector__XXX
 SG_ HitchCmd_RearHitchPosition : 31|1@1+ (1,0) [0|1] "" Vector__XXX
 SG_ NavigPseudorangeNoiseStatistic : 37|1@1+ (1,0) [0|1] "" Vector__XXX
 SG_ NavigSystemPositionData : 38|1@1+ (1,0) [0|1] "" Vector__XXX
 SG_ NavigSystemHighOutputPosition : 39|1@1+ (1,0) [0|1] "" Vector__XXX
 SG_ PTOCmd_FrontPTOEngagementCmd : 40|1@1+ (1,0) [0|1] "" Vector__XXX
 SG_ PTOCmd_FrontPTOSpeedCmd : 41|1@1+ (1,0) [0|1] "" Vector__XXX
 SG_ HitchCmd_FrontHitchPosition : 42|1@1+ (1,0) [0|1] "" Vector__XXX
 SG_ AddHitchParameter__FrontDraft : 43|1@1+ (1,0) [0|1] "" Vector__XXX
 SG_ PTOInfo_FrontShaftEngagement : 44|1@1+ (1,0) [0|1] "" Vector__XXX
 SG_ PTOInfo_FrontShaftSpeed : 45|1@1+ (1,0) [0|1] "" Vector__XXX
 SG_ HitchInfo_FrontInWork : 46|1@1+ (1,0) [0|1] "" Vector__XXX
 SG_ HitchInfo_FrontPosition : 47|1@1+ (1,0) [0|1] "" Vector__XXX
 SG_ ReservedBitIndicator : 56|1@1- (1,0) [0|1] "" Vector__XXX

BO_ 2358181630 SCMCC: 8 Vector__XXX
 SG_ MessageCode M : 0|8@1+ (1,0) [0|255] "" Vector__XXX
 SG_ LoadResponseError m7 : 8|8@1+ (1,0) [0|255] "" Vector__XXX
 SG_ StoreCommandError m6 : 8|8@1+ (1,0) [0|255] "" Vector__XXX
 SG_ DeleteCommandResponseError m5 : 8|8@1+ (1,0) [0|255] "" Vector__XXX
 SG_ CommandedSCCState m48 : 8|8@1+ (1,0) [0|1] "" Vector__XXX
 SG_ SCVersion m144 : 8|8@1+ (1,0) [0|255] "" Vector__XXX
 SG_ FunctionID m50 : 8|8@1+ (1,0) [0|255] "" Vector__XXX
 SG_ SCMState m149 : 8|8@1+ (1,0) [0|2] "" Vector__XXX
 SG_ ActivationResponseError m4 : 8|8@1+ (1,0) [0|255] "" Vector__XXX
 SG_ TransferResponseError m3 : 8|8@1+ (1,0) [0|255] "" Vector__XXX
 SG_ ConfigLabelResponseError m2M : 8|8@1+ (1,0) [0|255] "" Vector__XXX
 SG_ VersionResponseError m1M : 8|8@1+ (1,0) [0|255] "" Vector__XXX
 SG_ MemoryStatus m145 : 8|8@1+ (1,0) [0|1] "" Vector__XXX
 SG_ RecordedFunctionID m51 : 8|8@1+ (1,0) [0|255] "" Vector__XXX
 SG_ ObjectIdOfFirstFaultyObject m4 : 16|16@1+ (1,0) [0|65535] "" Vector__XXX
 SG_ SequenceNumber m149 : 16|8@1+ (1,0) [0|255] "" Vector__XXX
 SG_ RecordedStateID m51 : 16|6@1+ (1,0) [0|63] "" Vector__XXX
 SG_ GraphicsWidth m144 : 16|8@1+ (1,0) [32|255] "" Vector__XXX
 SG_ ActualVersionLabel m0 : 16|8@1+ (1,0) [0|255] "" Vector__XXX
 SG_ ActualConfigurationLabel m0 : 16|8@1+ (1,0) [0|255] "" Vector__XXX
 SG_ StateID m50 : 16|6@1+ (1,0) [0|63] "" Vector__XXX
 SG_ FunctionExecutionStateAck m52 : 22|2@1+ (1,0) [0|3] "" Vector__XXX
 SG_ FunctionExecutionState m50 : 22|2@1+ (1,0) [0|3] "" Vector__XXX
 SG_ GraphicsHeight m144 : 24|8@1+ (1,0) [32|255] "" Vector__XXX
 SG_ ReasonIndicator m48 : 24|8@1+ (1,0) [0|255] "" Vector__XXX
 SG_ SequenceState m149 : 24|8@1+ (1,0) [0|255] "" Vector__XXX
 SG_ TAN m51 : 24|8@1+ (1,0) [0|255] "" Vector__XXX
 SG_ ExecutionIndicationResponseError m50 : 24|8@1+ (1,0) [0|255] "" Vector__XXX
 SG_ BusyFlagMemoryAccess m149 : 32|1@1+ (1,0) [0|1] "" Vector__XXX
 SG_ RecordedFunctionValue m51 : 32|32@1+ (1,0) [0|4294967295] "" Vector__XXX
 SG_ ReceivedTAN m50 : 32|8@1+ (1,0) [0|255] "" Vector__XXX
 SG_ BusyFlagParsing m149 : 33|1@1+ (1,0) [0|1] "" Vector__XXX
 SG_ MaxDesignatorStringLength m144 : 32|16@1+ (1,0) [0|65535] "" Vector__XXX

BO_ 2358116094 SCCCM: 8 Vector__XXX
 SG_ MessageCode M : 0|8@1+ (1,0) [0|255] "" Vector__XXX
 SG_ DeleteCommandType m5 : 8|8@1+ (1,0) [0|1] "" Vector__XXX
 SG_ AddressSCCWSM m4 : 8|8@1+ (1,0) [0|253] "" Vector__XXX
 SG_ MemoryRequired m145 : 8|32@1+ (1,0) [0|4294967295] "" Vector__XXX
 SG_ FunctionID m50 : 8|8@1+ (1,0) [0|255] "" Vector__XXX
 SG_ SCCState m150 : 8|8@1+ (1,0) [0|2] "" Vector__XXX
 SG_ RecordedFunctionID m52 : 8|8@1+ (1,0) [0|255] "" Vector__XXX
 SG_ NumberOfFaultyFunctions m53M : 8|8@1+ (1,0) [0|255] "" Vector__XXX
 SG_ SequenceNumber m150 : 16|8@1+ (1,0) [0|255] "" Vector__XXX
 SG_ StateID m50 : 16|6@1+ (1,0) [0|63] "" Vector__XXX
 SG_ IDOfFaultyClientFunction1 m1 : 16|8@1+ (1,0) [0|255] "" Vector__XXX
 SG_ NewStateID m52 : 16|6@1+ (1,0) [0|63] "" Vector__XXX
 SG_ NewFunctionExecutionState m52 : 22|2@1+ (1,0) [0|3] "" Vector__XXX
 SG_ FunctionExecutionState m50M : 22|2@1+ (1,0) [0|3] "" Vector__XXX
 SG_ SequenceState m150 : 24|8@1+ (1,0) [0|255] "" Vector__XXX
 SG_ ClientAbortError m49 : 24|8@1+ (1,0) [0|255] "" Vector__XXX
 SG_ ClientFunctionErrorStatuts1 m1 : 24|4@1+ (1,0) [0|15] "" Vector__XXX
 SG_ ClientExecutionError m52 : 24|8@1+ (1,0) [0|255] "" Vector__XXX
 SG_ TAN m50 : 24|8@1+ (1,0) [0|255] "" Vector__XXX
 SG_ OperatorConfirmationRequired1 m1 : 31|1@1+ (1,0) [0|1] "" Vector__XXX
 SG_ ClientFunctonErrorState m150 : 32|8@1+ (1,0) [0|255] "" Vector__XXX
 SG_ IDOfFaultyClientFunction2 m2 : 32|8@1+ (1,0) [0|255] "" Vector__XXX
 SG_ FunctionValue m0 : 32|32@1+ (1,0) [0|4294967295] "" Vector__XXX
 SG_ ReceivedTAN m52 : 32|8@1+ (1,0) [0|255] "" Vector__XXX
 SG_ ClientFunctionErrorStatuts2 m2 : 40|4@1+ (1,0) [0|15] "" Vector__XXX
 SG_ OperatorConfirmationRequired2 m2 : 47|1@1+ (1,0) [0|1] "" Vector__XXX
 SG_ IDOfFaultyClientFunction3 m3 : 48|8@1+ (1,0) [0|255] "" Vector__XXX
 SG_ ClientFunctionErrorStatuts3 m3 : 56|4@1+ (1,0) [0|15] "" Vector__XXX
 SG_ OperatorConfirmationRequired3 m3 : 63|1@1+ (1,0) [0|1] "" Vector__XXX

BO_ 2365458686 RTF: 8 Vector__XXX
 SG_ SpeedInfo_EngineSpeed : 0|1@1+ (1,0) [0|1] "" Vector__XXX
 SG_ SpeedInfo_GroundBasedSpeed : 1|1@1+ (1,0) [0|1] "" Vector__XXX
 SG_ SpeedInfo_WheelBasedSpeed : 2|1@1+ (1,0) [0|1] "" Vector__XXX
 SG_ PowerMgt_MaintainPower : 3|1@1+ (1,0) [0|1] "" Vector__XXX
 SG_ PowerMgt_MaxTimeTractorPower : 4|1@1+ (1,0) [0|1] "" Vector__XXX
 SG_ PowerMgt_KeySwitch : 5|1@1+ (1,0) [0|1] "" Vector__XXX
 SG_ TractorClass : 6|2@1+ (1,0) [0|3] "" Vector__XXX
 SG_ LanguageCmdStorageInTractorECU : 10|1@1+ (1,0) [0|1] "" Vector__XXX
 SG_ Lighting_MinimalSet : 11|1@1+ (1,0) [0|1] "" Vector__XXX
 SG_ PTOInfo_RearShaftEngagement : 12|1@1+ (1,0) [0|0] "" Vector__XXX
 SG_ PTOInfo_RearShaftSpeed : 13|1@1+ (1,0) [0|1] "" Vector__XXX
 SG_ HitchInfo_RearInWork : 14|1@1+ (1,0) [0|1] "" Vector__XXX
 SG_ HitchInfo_RearPosition : 15|1@1+ (1,0) [0|1] "" Vector__XXX
 SG_ EstimatedOrMeasuredAuxValveState : 16|1@1+ (1,0) [0|1] "" Vector__XXX
 SG_ Light_FullImplLightingMessageSet : 17|1@1+ (1,0) [0|1] "" Vector__XXX
 SG_ AddHitchParameter_RearDraft : 18|1@1+ (1,0) [0|1] "" Vector__XXX
 SG_ SpeedAndDist_WheelBasedDirection : 19|1@1+ (1,0) [0|1] "" Vector__XXX
 SG_ SpeedAndDist_WheelBasedDistance : 20|1@1+ (1,0) [0|1] "" Vector__XXX
 SG_ SpeedAndDist_GndBasedDirection : 21|1@1+ (1,0) [0|1] "" Vector__XXX
 SG_ SpeedAndDist_GndBasedDistance : 22|1@1+ (1,0) [0|1] "" Vector__XXX
 SG_ TimeDate : 23|1@1+ (1,0) [0|1] "" Vector__XXX
 SG_ LimitStatusReporting : 27|1@1+ (1,0) [0|0] "" Vector__XXX
 SG_ AuxiliaryValveCmd : 28|1@1+ (1,0) [0|1] "" Vector__XXX
 SG_ PTOCmd_RearPTOEngagementCmd : 29|1@1+ (1,0) [0|1] "" Vector__XXX
 SG_ PTOCmd_RearPTOSpeedCmd : 30|1@1+ (1,0) [0|1] "" Vector__XXX
 SG_ HitchCmd_RearHitchPosition : 31|1@1+ (1,0) [0|1] "" Vector__XXX
 SG_ DirectionControl : 32|1@1+ (1,0) [0|1] "" Vector__XXX
 SG_ SelectedMachineSpeedControl : 33|1@1+ (1,0) [0|1] "" Vector__XXX
 SG_ SelectedMachineSpeed : 34|1@1+ (1,0) [0|1] "" Vector__XXX
 SG_ OperatorExternalLightControls : 35|1@1+ (1,0) [0|1] "" Vector__XXX
 SG_ NavigPseudorangeNoiseStatistic : 37|1@1+ (1,0) [0|1] "" Vector__XXX
 SG_ NavigSystemPositionData : 38|1@1+ (1,0) [0|1] "" Vector__XXX
 SG_ NavigSystemHighOutputPosition : 39|1@1+ (1,0) [0|1] "" Vector__XXX
 SG_ PTOCmd_FrontPTOEngagementCmd : 40|1@1+ (1,0) [0|1] "" Vector__XXX
 SG_ PTOCmd_FrontPTOSpeedCmd : 41|1@1+ (1,0) [0|1] "" Vector__XXX
 SG_ HitchCmd_FrontHitchPosition : 42|1@1+ (1,0) [0|1] "" Vector__XXX
 SG_ AddHitchParameter__FrontDraft : 43|1@1+ (1,0) [0|1] "" Vector__XXX
 SG_ PTOInfo_FrontShaftEngagement : 44|1@1+ (1,0) [0|1] "" Vector__XXX
 SG_ PTOInfo_FrontShaftSpeed : 45|1@1+ (1,0) [0|1] "" Vector__XXX
 SG_ HitchInfo_FrontInWork : 46|1@1+ (1,0) [0|1] "" Vector__XXX
 SG_ HitchInfo_FrontPosition : 47|1@1+ (1,0) [0|1] "" Vector__XXX
 SG_ ReservedBitIndicator : 56|1@1- (1,0) [0|1] "" Vector__XXX

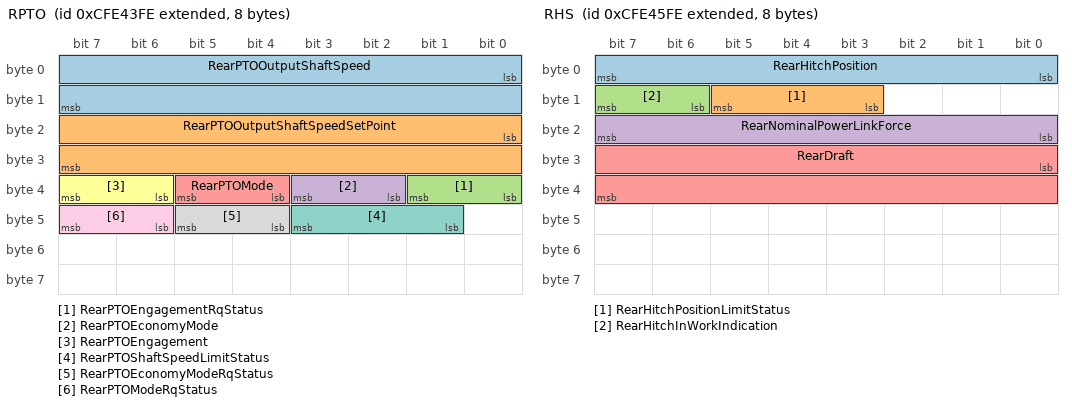
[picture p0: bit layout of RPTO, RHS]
BO_ 2365473790 RPTO: 8 Vector__XXX
 SG_ RearPTOOutputShaftSpeed : 0|16@1+ (0.125,0) [0|8031.88] "1/min" Vector__XXX
 SG_ RearPTOOutputShaftSpeedSetPoint : 16|16@1+ (0.125,0) [0|8031.88] "1/min" Vector__XXX
 SG_ RearPTOEngagementRqStatus : 32|2@1+ (1,0) [0|3] "" Vector__XXX
 SG_ RearPTOEconomyMode : 34|2@1+ (1,0) [0|3] "" Vector__XXX
 SG_ RearPTOMode : 36|2@1+ (1,0) [0|3] "" Vector__XXX
 SG_ RearPTOEngagement : 38|2@1+ (1,0) [0|3] "" Vector__XXX
 SG_ RearPTOShaftSpeedLimitStatus : 41|3@1+ (1,0) [0|7] "" Vector__XXX
 SG_ RearPTOEconomyModeRqStatus : 44|2@1+ (1,0) [0|3] "" Vector__XXX
 SG_ RearPTOModeRqStatus : 46|2@1+ (1,0) [0|3] "" Vector__XXX

BO_ 2365474302 RHS: 8 Vector__XXX
 SG_ RearHitchPosition : 0|8@1+ (0.4,0) [0|100] "%" Vector__XXX
 SG_ RearHitchPositionLimitStatus : 11|3@1+ (1,0) [0|7] "" Vector__XXX
 SG_ RearHitchInWorkIndication : 14|2@1+ (1,0) [0|3] "" Vector__XXX
 SG_ RearNominalPowerLinkForce : 16|8@1+ (0.8,-100) [-100|100] "%" Vector__XXX
 SG_ RearDraft : 24|16@1+ (10,-320000) [-320000|322550] "N" Vector__XXX

BO_ 2566786814 RESRR: 8 Vector__XXX
 SG_ PGN : 0|24@1+ (1,0) [0|16777200] "" Vector__XXX
 SG_ ActualRepetitionRate : 24|16@1+ (1,0) [0|64255] "ms" Vector__XXX

BO_ 2563571454 REQRR: 8 Vector__XXX
 SG_ RequestedPGN : 0|24@1+ (1,0) [0|16777200] "" Vector__XXX
 SG_ RepetitionRateCmd : 24|16@1+ (1,0) [0|64255] "ms" Vector__XXX

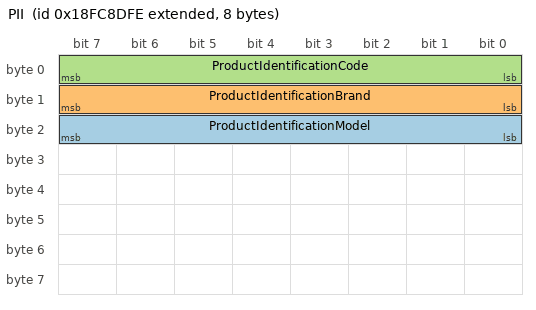
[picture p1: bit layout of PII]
BO_ 2566688254 PII: 8 Vector__XXX
 SG_ ProductIdentificationModel : 16|8@1- (1,0) [0|0] "" Vector__XXX
 SG_ ProductIdentificationBrand : 8|8@1- (1,0) [0|0] "" Vector__XXX
 SG_ ProductIdentificationCode : 0|8@1- (1,0) [0|0] "" Vector__XXX

CM_ BO_ 2632384254 "VT to ECU";
CM_ SG_ 2632384254 AnalogValue "Analog value of 0xFFFF if input type is boolean";
CM_ SG_ 2632384254 AuxInputEnable "Auxiliary Input Enable";
CM_ SG_ 2632384254 ErrorCodeAnyOtherError "VT change mask error code: Any other error";
CM_ SG_ 2632384254 ErrorCodePoolDeleted "VT change mask error code: Pool being deleted";
CM_ SG_ 2632384254 NumTransitionsDisabledToEnabled "Number of transitions of disabled to enabled";
CM_ SG_ 2632384254 VTChangeActiveMaskErrorID "Object ID containing error";
CM_ SG_ 2632384254 VTChangeActiveMaskParentID "Parent object ID of error object ID";
CM_ SG_ 2632384254 AuxiliaryFunctionType "Auxiliary function type of assigned auxiliary input";
CM_ BO_ 2365458942 "Tractor Facilities response message";
CM_ SG_ 2365458942 LimitStatusReporting "Parameter used to respond to a request of a facility of a tractor ECU";
CM_ BO_ 2358181630 "Sequence Control Master to Sequence Control Client";
CM_ SG_ 2358181630 MessageCode "Message code of the SCMCC message";
CM_ SG_ 2358181630 SCVersion "Version of supported SC standard";
CM_ SG_ 2358181630 SCMState "State of sending SCM";
CM_ SG_ 2358181630 TransferResponseError "Error code of the SCDTransferResponse";
CM_ SG_ 2358181630 ConfigLabelResponseError "Error code of SCDConfigurationLabelResponse";
CM_ SG_ 2358181630 VersionResponseError "Error code of the SCDVersionResponse";
CM_ SG_ 2358181630 ObjectIdOfFirstFaultyObject "Object ID of first faulty object";
CM_ SG_ 2358181630 GraphicsWidth "Number of pixels on the X axis for graphics objects";
CM_ SG_ 2358181630 GraphicsHeight "Number of pixels on the Y axis for graphics objects";
CM_ SG_ 2358181630 MaxDesignatorStringLength "Maximum number of displayed characters for designator strings";
CM_ BO_ 2358116094 "Sequence Control Client to Sequence Control Master";
CM_ SG_ 2358116094 MessageCode "Message code of the SCMCC message";
CM_ SG_ 2358116094 AddressSCCWSM "Source address of SCC's working set master";
CM_ SG_ 2358116094 ClientAbortError "Error code of a SCClientAbort";
CM_ BO_ 2365458686 "Required Tractor Facilities message";
CM_ SG_ 2365458686 LimitStatusReporting "Parameter used to respond to a request of a facility of a tractor ECU";
CM_ SG_ 2365458686 DirectionControl "Parameter used to respond to a request of a facility of a tractor ECU";
CM_ SG_ 2365458686 SelectedMachineSpeedControl "Parameter used to respond to a request of a facility of a tractor ECU";
CM_ SG_ 2365458686 SelectedMachineSpeed "Parameter used to respond to a request of a facility of a tractor ECU";
CM_ SG_ 2365458686 OperatorExternalLightControls "Parameter used to respond to a request of a facility of a tractor ECU";
CM_ BO_ 2365473790 "Primary or Rear Power Take off Output Shaft
";
CM_ SG_ 2365473790 RearPTOEngagementRqStatus "Parameter used to report the tractor ECUs status associated with a parameter whose requests are transient.";
CM_ SG_ 2365473790 RearPTOShaftSpeedLimitStatus "Parameter used to report the tractor ECUs present limit status associated with a parameter whose commands are persistent";
CM_ SG_ 2365473790 RearPTOEconomyModeRqStatus "Parameter used to report the tractor ECUs status associated with a parameter whose requests are transient.";
CM_ SG_ 2365473790 RearPTOModeRqStatus "Parameter used to report the tractor ECUs status associated with a parameter whose requests are transient.";
CM_ BO_ 2365474302 "Primary or Rear Hitch Status";
CM_ SG_ 2365474302 RearHitchPositionLimitStatus "Parameter used to report the tractor ECUs present limit status associated with a parameter whose commands are persistent";
CM_ BO_ 2566786814 "Response for Repetition Rate";
CM_ BO_ 2563571454 "Request for Repetition Rates";
CM_ BO_ 2566688254 "Product Identification Information: Each control function of a product shall respond with the same product identification information when it 
receives the Request PGN message for this PGN.";
CM_ SG_ 2566688254 ProductIdentificationModel "The Product Identification Model specifies a unique product within a Brand. ";
CM_ SG_ 2566688254 ProductIdentificationBrand "Specifies  the  brand  of  a  product.  
The  combination  of  the  Product Identification Code and the Product Identification Brand shall make the product unique in the world.";
CM_ SG_ 2566688254 ProductIdentificationCode "The Product Identification Code as assigned by the manufacturer correspondents with the number on the type 
plate of a product.";
BA_DEF_ BO_  "GenMsgCycleTimeFast" INT 0 3600000;
BA_DEF_ SG_  "SigType" ENUM  "Default","Range","RangeSigned","ASCII","Discrete","Control","ReferencePGN","DTC","StringDelimiter","StringLength","StringLengthControl";
BA_DEF_ SG_  "GenSigStartValue" INT 0 10000;
BA_DEF_ SG_  "GenSigSendType" ENUM  "Cyclic","OnWrite","reserved","OnChange","reserved","reserved","reserved","NoSigSendType";
BA_DEF_ SG_  "GenSigILSupport" ENUM  "Yes","No";
BA_DEF_ SG_  "GenSigEVName" STRING ;
BA_DEF_ SG_  "SPN" INT 0 524287;
BA_DEF_ SG_  "DDI" INT 0 65535;
BA_DEF_ SG_  "SAEDocument" STRING ;
BA_DEF_ BO_  "GenMsgStartDelayTime" INT 0 100000;
BA_DEF_ BO_  "GenMsgILSupport" ENUM  "Yes","No";
BA_DEF_ BO_  "GenMsgRequestable" INT 0 1;
BA_DEF_ BO_  "GenMsgSendType" ENUM  "cyclic","reserved","cyclicIfActive","reserved","reserved","reserved","reserved","reserved","noMsgSendType";
BA_DEF_ BO_  "VFrameFormat" ENUM  "StandardCAN","ExtendedCAN","reserved","J1939PG";
BA_DEF_ BO_  "SingleFrame" INT 0 1;
BA_DEF_ BO_  "GenMsgCycleTime" INT 0 3600000;
BA_DEF_ BO_  "SAE_Document" STRING ;
BA_DEF_ SG_  "SystemSignalLongSymbol" STRING ;
BA_DEF_DEF_  "GenMsgCycleTimeFast" 0;
BA_DEF_DEF_  "SigType" "Default";
BA_DEF_DEF_  "GenSigStartValue" 0;
BA_DEF_DEF_  "GenSigSendType" "NoSigSendType";
BA_DEF_DEF_  "GenSigILSupport" "Yes";
BA_DEF_DEF_  "GenSigEVName" "Env@Nodename_@Signame";
BA_DEF_DEF_  "SPN" 0;
BA_DEF_DEF_  "DDI" 0;
BA_DEF_DEF_  "SAEDocument" "";
BA_DEF_DEF_  "GenMsgStartDelayTime" 0;
BA_DEF_DEF_  "GenMsgILSupport" "Yes";
BA_DEF_DEF_  "GenMsgRequestable" 1;
BA_DEF_DEF_  "GenMsgSendType" "noMsgSendType";
BA_DEF_DEF_  "VFrameFormat" "J1939PG";
BA_DEF_DEF_  "SingleFrame" 1;
BA_DEF_DEF_  "GenMsgCycleTime" 0;
BA_DEF_DEF_  "SAE_Document" "";
BA_DEF_DEF_  "SystemSignalLongSymbol" "";
BA_ "GenMsgCycleTime" BO_ 2632384254 100;
BA_ "GenMsgCycleTime" BO_ 2365458942 100;
BA_ "GenMsgCycleTime" BO_ 2365458686 100;
BA_ "GenMsgCycleTime" BO_ 2365473790 100;
BA_ "GenMsgCycleTime" BO_ 2365474302 100;
BA_ "GenMsgCycleTime" BO_ 2566786814 100;
BA_ "GenMsgCycleTime" BO_ 2563571454 100;
BA_ "SPN" SG_ 2632384254 IdentityNumber 2837;
BA_ "SAEDocument" SG_ 2632384254 IdentityNumber "J1939-81";
BA_ "SystemSignalLongSymbol" SG_ 2632384254 ChangeChildLocationParentOb_0001 "ChangeChildLocationParentObjectID";
BA_ "SystemSignalLongSymbol" SG_ 2632384254 ChangeChildPositionParentOb_0001 "ChangeChildPositionParentObjectID";
BA_ "SystemSignalLongSymbol" SG_ 2632384254 BckgndColourUserLayoutSoftkeyMas "BckgndColourUserLayoutSoftkeyMask";
BA_ "SigType" SG_ 2632384254 VersionLables 3;
BA_ "SigType" SG_ 2632384254 ExtendedVersionLables 3;
BA_ "SigType" SG_ 2632384254 EnteredStringValue 9;
BA_ "SigType" SG_ 2632384254 ManufacturerCode 1;
BA_ "SPN" SG_ 2632384254 ManufacturerCode 2838;
BA_ "SAEDocument" SG_ 2632384254 ManufacturerCode "NMEA2000";
BA_ "SPN" SG_ 2632384254 ECUInstance 2840;
BA_ "SAEDocument" SG_ 2632384254 ECUInstance "J1939-81";
BA_ "SPN" SG_ 2632384254 FunctionInstance 2839;
BA_ "SAEDocument" SG_ 2632384254 FunctionInstance "J1939-81";
BA_ "SPN" SG_ 2632384254 Function 2841;
BA_ "SAEDocument" SG_ 2632384254 Function "J1939-81";
BA_ "SPN" SG_ 2632384254 IndustryGroup 2846;
BA_ "SAEDocument" SG_ 2632384254 IndustryGroup "NMEA2000";
BA_ "SPN" SG_ 2365458942 SpeedInfo_EngineSpeed 5235;
BA_ "SPN" SG_ 2365458942 TractorClass 5234;
BA_ "SigType" SG_ 2365458942 TractorClass 4;
BA_ "SPN" SG_ 2365458942 ReservedBitIndicator 5236;
BA_ "SigType" SG_ 2358181630 SequenceNumber 1;
BA_ "GenSigStartValue" SG_ 2358181630 SequenceNumber 1;
BA_ "SPN" SG_ 2358181630 SequenceNumber 2572;
BA_ "SAEDocument" SG_ 2358181630 SequenceNumber "J1939-21";
BA_ "GenSigStartValue" SG_ 2358181630 GraphicsWidth 32;
BA_ "SigType" SG_ 2358181630 ActualVersionLabel 9;
BA_ "SigType" SG_ 2358181630 ActualConfigurationLabel 9;
BA_ "GenSigStartValue" SG_ 2358181630 GraphicsHeight 32;
BA_ "SigType" SG_ 2358116094 SequenceNumber 1;
BA_ "GenSigStartValue" SG_ 2358116094 SequenceNumber 1;
BA_ "SPN" SG_ 2358116094 SequenceNumber 2572;
BA_ "SAEDocument" SG_ 2358116094 SequenceNumber "J1939-21";
BA_ "SPN" SG_ 2365458686 SpeedInfo_EngineSpeed 5235;
BA_ "SPN" SG_ 2365458686 TractorClass 5234;
BA_ "SigType" SG_ 2365458686 TractorClass 4;
BA_ "SPN" SG_ 2365458686 ReservedBitIndicator 5236;
BA_ "SPN" SG_ 2365473790 RearPTOOutputShaftSpeed 1883;
BA_ "SigType" SG_ 2365473790 RearPTOOutputShaftSpeed 1;
BA_ "SPN" SG_ 2365473790 RearPTOOutputShaftSpeedSetPoint 1885;
BA_ "SigType" SG_ 2365473790 RearPTOOutputShaftSpeedSetPoint 1;
BA_ "SPN" SG_ 2365473790 RearPTOEngagementRqStatus 5156;
BA_ "SigType" SG_ 2365473790 RearPTOEngagementRqStatus 4;
BA_ "SPN" SG_ 2365473790 RearPTOEconomyMode 1892;
BA_ "SigType" SG_ 2365473790 RearPTOEconomyMode 4;
BA_ "SPN" SG_ 2365473790 RearPTOMode 1890;
BA_ "SigType" SG_ 2365473790 RearPTOMode 4;
BA_ "SPN" SG_ 2365473790 RearPTOEngagement 2408;
BA_ "SigType" SG_ 2365473790 RearPTOEngagement 4;
BA_ "SPN" SG_ 2365473790 RearPTOShaftSpeedLimitStatus 5159;
BA_ "SPN" SG_ 2365473790 RearPTOEconomyModeRqStatus 5158;
BA_ "SigType" SG_ 2365473790 RearPTOEconomyModeRqStatus 4;
BA_ "SPN" SG_ 2365473790 RearPTOModeRqStatus 5157;
BA_ "SigType" SG_ 2365473790 RearPTOModeRqStatus 4;
BA_ "SPN" SG_ 2365474302 RearHitchPosition 1873;
BA_ "SigType" SG_ 2365474302 RearHitchPosition 1;
BA_ "SPN" SG_ 2365474302 RearHitchPositionLimitStatus 5151;
BA_ "SPN" SG_ 2365474302 RearHitchInWorkIndication 1877;
BA_ "SigType" SG_ 2365474302 RearHitchInWorkIndication 4;
BA_ "SPN" SG_ 2365474302 RearNominalPowerLinkForce 1881;
BA_ "SigType" SG_ 2365474302 RearNominalPowerLinkForce 1;
BA_ "SPN" SG_ 2365474302 RearDraft 1879;
BA_ "SigType" SG_ 2365474302 RearDraft 1;
BA_ "SigType" SG_ 2566786814 PGN 6;
BA_ "SPN" SG_ 2566786814 ActualRepetitionRate 5198;
BA_ "SigType" SG_ 2566786814 ActualRepetitionRate 1;
BA_ "SigType" SG_ 2563571454 RequestedPGN 6;
BA_ "SPN" SG_ 2563571454 RepetitionRateCmd 2418;
BA_ "SigType" SG_ 2563571454 RepetitionRateCmd 1;
BA_ "SPN" SG_ 2566688254 ProductIdentificationModel 6701;
BA_ "SigType" SG_ 2566688254 ProductIdentificationModel 8;
BA_ "SPN" SG_ 2566688254 ProductIdentificationBrand 6701;
BA_ "SigType" SG_ 2566688254 ProductIdentificationBrand 8;
BA_ "SPN" SG_ 2566688254 ProductIdentificationCode 6699;
BA_ "SigType" SG_ 2566688254 ProductIdentificationCode 8;
VAL_ 2632384254 VTFunctionVTtoECU 39 " AuxiliaryCapabilitiesResponse" 214 "ExtendedDeleteVersionResponse" 213 "ExtendedLoadVersionResponse" 212 "ExtendedStoreVersionResponse" 211 "ExtendedGetVersionsResponse" 191 "ExecuteOpCodeResponse" 188 "ExecuteExtendedMacroResponse" 11 "VTOpCodeNotification" 197 "GetSupportedObjectsResponse" 187 "IdentifyVTResponse" 38 "AuxiliaryInputStatusType2" 36 "AuxiliaryAssignmentCommandType2" 193 "GetSupported WideCharsResponse" 37 "AuxiliaryInputStatusEnableCommand" 190 "ExecuteMacroResponse" 189 "LockUnlockMaskResponse" 35 "AuxiliaryInputMaintenance" 10 "VTControlAudioDeviceTermination" 9 "VTOnUserLayoutHideShow" 186 "SelectColourMapResponse" 185 "GetAttributeValueResponse" 184 "GraphicsContextCommandResponse" 183 "ChangePolygonScaleResponse" 182 "ChangePolygonPointResponse" 181 "SetObjectLabelResponse" 0 "SoftKeyActivation" 1 "ButtonActivation" 2 "PointingEvent" 18 "EndOfObjectPoolResponse" 32 "AuxiliaryAssignmentCommand" 146 "ESCResponse" 160 "ShowHideObjectResponse" 161 "EnableDisableObjectResponse" 162 "SelectInputObjectResponse" 163 "ControlAudioDeviceResponse" 164 "SetAudioVolumeResponse" 165 "ChangeChildLocationResponse" 166 "ChangeSizeResponse" 167 "ChangeBackgroundColourResponse" 168 "ChangeNumericValueResponse" 169 "ChangeEndPointResponse" 170 "ChangeFontAttributesResponse" 171 "ChangeLineAttributesResponse" 172 "ChangeFillAttributesResponse" 173 "ChangeActiveMaskResponse" 174 "ChangeSoftKeyMaskResponse" 175 "ChangeAttributeResponse" 176 "ChangePriorityResponse" 177 "ChangeListItemResponse" 178 "DeleteObjectPoolResponse" 192 "GetMemoryResponse" 194 "GetNumberOfSoftKeysResponse" 195 "GetTextFontDataResponse" 199 "GetHardwareResponse" 208 "StoreVersionResponse" 209 "LoadVersionResponse" 210 "DeleteVersionResponse" 224 "GetVersionsResponse" 254 "VTStatusMessage" 33 "AuxiliaryInputStatus" 3 "VTSelectInputObject" 4 "VTESC" 5 "VTChangeNumericValue" 6 "VTChangeActiveMask" 7 "VTChangeSoftKeyMask" 8 "VTChangeStringValue" 196 "GetWindowMaskDataResponse" 240 "VTObjectPoolErrorMessage" 179 "ChangeStringValueResponse" 180 "ChangeChildPositionResponse" 34 "AuxiliaryPreferredAssignmentResponse" ;
VAL_ 2632384254 BootTime 255 "Information not available" ;
VAL_ 2632384254 TerminationCause 1 "AudioWasTerminated" ;
VAL_ 2632384254 KeyActivationCode 3 "KeyPressAborted" 0 "KeyHasBeenReleased" 1 "KeyHasBeenPressed" 2 "KeyIsStillHeld" ;
VAL_ 2632384254 ButtonActivationCode 3 "ButtonPressAborted" 0 "ButtonHasBeenUnlatched" 1 "ButtonHasBeenLatched" 2 "ButtonsStillHeld" ;
VAL_ 2632384254 ErrorCodeEndOfObjectPool1 1 "ErrorsInTheObjectPool" 0 "NoErrors" ;
VAL_ 2632384254 AuxPreferredAssignmentRespError1 1 "AuxiliaryInputUnit(s)NotValid" 0 "NoErrors" ;
VAL_ 2632384254 ErrorCodeControlAudioDevice1 0 "NoErrors" 1 "AudioDeviceIsBusy" ;
VAL_ 2632384254 ErrorCodeAudioVolume1 0 "NoErrors" 1 "AudioDeviceIsBusy" ;
VAL_ 2632384254 ErrorCodeDeleteObjectPool1 0 "NoErrors" 1 "DeletionError" ;
VAL_ 2632384254 ErrorCodeSetObjectLabel1 1 "InvalidObjectId" 0 "NoError" ;
VAL_ 2632384254 LockUnlockCommand 1 "LockMask" 0 "UnlockMask" ;
VAL_ 2632384254 VersionNumberISO11783Part6 0 "Hannover Agritechnica 2001 limit" 1 "FDIS_Version" 2 "VersionOfThe1PublishedEdition" 3 "VersionOfThe2PublishedEdition" 4 "VersionOfThe3PublishedEdition" 5 "VersionOfThe4PublishedEdition" 6 "VersionOfThe5PublishedEdition" 7 "VersionOfThe6PublishedEdition" 8 "VersionOfThe7PublishedEdition" 9 "VersionOfThe8PublishedEdition" 10 "VersionOfThe9PublishedEdition" 11 "VersionOfThe10PublishedEdition" 12 "VersionOfThe11PublishedEdition" 13 "VersionOfThe12PublishedEdition" 14 "VersionOfThe13PublishedEdition" 15 "VersionOfThe14PublishedEdition" 16 "VersionOfThe15PublishedEdition" 17 "VersionOfThe16PublishedEdition" 18 "VersionOfThe17PublishedEdition" 19 "VersionOfThe18PublishedEdition" 20 "VersionOfThe19PublishedEdition" 21 "VersionOfThe20PublishedEdition" 22 "VersionOfThe21PublishedEdition" 23 "VersionOfThe22PublishedEdition" 24 "VersionOfThe23PublishedEdition" 25 "VersionOfThe24PublishedEdition" 26 "VersionOfThe25PublishedEdition" 27 "VersionOfThe26PublishedEdition" 28 "VersionOfThe27PublishedEdition" 29 "VersionOfThe28PublishedEdition" 30 "VersionOfThe29PublishedEdition" 31 "VersionOfThe30PublishedEdition" 32 "VersionOfThe31PublishedEdition" 33 "VersionOfThe32PublishedEdition" 34 "VersionOfThe33PublishedEdition" 35 "VersionOfThe34PublishedEdition" 36 "VersionOfThe35PublishedEdition" 37 "VersionOfThe36PublishedEdition" 38 "VersionOfThe37PublishedEdition" 39 "VersionOfThe38PublishedEdition" 40 "VersionOfThe39PublishedEdition" 41 "VersionOfThe40PublishedEdition" 42 "VersionOfThe41PublishedEdition" 43 "VersionOfThe42PublishedEdition" 44 "VersionOfThe43PublishedEdition" 45 "VersionOfThe44PublishedEdition" 46 "VersionOfThe45PublishedEdition" 47 "VersionOfThe46PublishedEdition" 48 "VersionOfThe47PublishedEdition" 49 "VersionOfThe48PublishedEdition" 50 "VersionOfThe50PublishedEdition" ;
VAL_ 2632384254 ErrorCodeEndOfObjectPool2 0 "NoErrors" 1 "VTRanOutOfMemoryDuringTransfer" ;
VAL_ 2632384254 AuxPreferredAssignmentRespError2 1 "FunctionObjectID(s)NotValid" 0 "NoErrors" ;
VAL_ 2632384254 ErrorCodeSetObjectLabel2 1 "InvalidStringVariableObjectId" 0 "NoError" ;
VAL_ 2632384254 AuxPreferredAssignmentRespError3 1 "InputObjectID(s)NotValid" 0 "NoErrors" ;
VAL_ 2632384254 ErrorCodeSetObjectLabel3 1 "InvalidFontType" 0 "NoError" ;
VAL_ 2632384254 AuxPreferredAssignmentRespError4 1 "DuplicateObjectIdOfAuxFct" 0 "NoErrors" ;
VAL_ 2632384254 ErrorCodeSetObjectLabel4 1 "InvalidDesignatorObjectReference" 0 "NoError" ;
VAL_ 2632384254 AuxPreferredAssignmentRespError5 1 "GeneralError" 0 "NoErrors" ;
VAL_ 2632384254 ErrorCodeEndOfObjectPool3 0 "NoErrors" 1 "GeneralError" ;
VAL_ 2632384254 ErrorCodeControlAudioDevice2 0 "NoErrors" 1 "GeneralError" ;
VAL_ 2632384254 ErrorCodeAudioVolume2 0 "NoErrors" 1 "GeneralError" ;
VAL_ 2632384254 ErrorCodeDeleteObjectPool2 0 "NoErrors" 1 "GeneralError" ;
VAL_ 2632384254 ErrorCodeSetObjectLabel5 1 "DesignatorReferencesInvalidObjects" 0 "NoError" ;
VAL_ 2632384254 ErrorCodeSetObjectLabel6 1 "GeneralError" 0 "NoError" ;
VAL_ 2632384254 KeyObjectID 0 "KeyHasBeenReleased" 1 "KeyHasBeenPressed" 2 "KeyIsStillHeld" ;
VAL_ 2632384254 ButtonObjectID 0 "ButtonHasBeenUnlatched" 1 "ButtonHasBeenLatched" 2 "ButtonsStillHeld" ;
VAL_ 2632384254 ErrorCodeLockUnlockMask1 1 "MaskNotVisibleOrInvalidObjectId" 0 "NoError" ;
VAL_ 2632384254 ErrorCodeExecuteMacro1 1 "ObjectIdNotExist" 0 "NoError" ;
VAL_ 2632384254 MemoryStatus 0 "EnoughMemoryMayBeAvailable" 1 "NotEnoughMemoryAvailable" ;
VAL_ 2632384254 SupportedGraphicMode 0 "Monocrome" 1 "Colour16" 2 "Colour256" ;
VAL_ 2632384254 ErrorCodeLockUnlockMask2 1 "MaskAlreadyLocked" 0 "NoError" ;
VAL_ 2632384254 ErrorCodeExecuteMacro2 1 "ObjectIdIsNoMacro" 0 "NoError" ;
VAL_ 2632384254 ErrorCodeLockUnlockMask3 1 "MaskNotLocked" 0 "NoError" ;
VAL_ 2632384254 ErrorCodeExecuteMacro3 1 "GeneralError" 0 "NoError" ;
VAL_ 2632384254 ErrorCodeLockUnlockMask4 1 "AlarmMaskIsActive" 0 "NoError" ;
VAL_ 2632384254 ErrorCodeLockUnlockMask5 1 "UnsolicitedUnlock_TimeoutOccured" 0 "NoError" ;
VAL_ 2632384254 ErrorCodeLockUnlockMask6 1 "UnsolicitedUnlock_MaskChanged" 0 "NoError" ;
VAL_ 2632384254 ErrorCodeLockUnlockMask7 1 "UnsolicitedUnlock_OperatorInduce" 0 "NoError" ;
VAL_ 2632384254 ErrorCodeLockUnlockMask8 1 "GeneralError" 0 "NoError" ;
VAL_ 2632384254 Status_1 1 "Shown" 0 "Hidden" ;
VAL_ 2632384254 VTSelectInputObjectStatus 0 "ObjectIsDeselected" 1 "ObjectIsSelected" ;
VAL_ 2632384254 ErrorCodeVTEsc1 0 "NoError" 1 "NoInputFieldSelected ESC_Ignored" ;
VAL_ 2632384254 ErrorCodeEscapeObj1 0 "NoErrors" 1 "NoInputFieldIsOpenForInput" ;
VAL_ 2632384254 ObjectShowStatus 0 "ObjectIsHidden" 1 "ObjectIsShown" ;
VAL_ 2632384254 ObjectEnableStatus 0 "ObjectIsDisabled" 1 "ObjectIsEnabled" ;
VAL_ 2632384254 ObjectSelectStatus 2 "ObjectIsOpenedForEdit" 0 "ObjectIsDeselectedOrObjectIDIsNullObject" 1 "ObjectIsSelected" ;
VAL_ 2632384254 ErrorCodeObjToSize1 0 "NoErrors" 1 "InvalidObjectID" ;
VAL_ 2632384254 ErrorCodeChangeNumValue1 0 "NoErrors" 1 "InvalidObjectID" ;
VAL_ 2632384254 ErrorCodeChangeEditPoint1 0 "NoErrors" 1 "InvalidObjectID" ;
VAL_ 2632384254 ErrorCodeChangeFont1 0 "NoErrors" 1 "InvalidObjectID" ;
VAL_ 2632384254 ErrorCodeChangeLineAttribute1 0 "NoErrors" 1 "InvalidObjectID" ;
VAL_ 2632384254 ErrorCodeChangeFillAttributes1 0 "NoErrors" 1 "InvalidObjectID" ;
VAL_ 2632384254 ErrorCodeChangeActiveMask1 0 "NoErrors" 1 "InvalidWorkingSetObject" ;
VAL_ 2632384254 ErrorCodeChangePoygonPoint1 1 "InvalidObjectId" 0 "NoError" ;
VAL_ 2632384254 SubCommandID 20 "CopyViewportToPictureGraphic" 19 "CopyCanvasToPictureGraphic" 18 "DrawVTObject" 17 "ChangeViewportSize" 16 "PanAndZoomViewport" 15 "ZoomViewport" 14 "PanViewport" 13 "DrawText" 12 "DrawPolygon" 11 "DrawClosedEllipse" 10 "DrawRectangle" 9 "DrawLine" 8 "DrawPoint" 7 "EraseRectangle" 6 "SetFontAttributesID" 5 "SetFillAttributesObjectID" 4 "SetLineAttributesObjectID" 3 "SetBackgroundColour" 2 "SetForegroundColour" 1 "MoveGraphicsCursor" 0 "SetGraphicsCursor" ;
VAL_ 2632384254 ErrorCodeSelectColourMap1 1 "InvalidObjectID" 0 "NoError" ;
VAL_ 2632384254 Hardware1 0 "VT has no touch screen and no pointing device" 1 "VT has a touch screen or pointing device" ;
VAL_ 2632384254 ErrorCodeExecuteOpCode1 1 "LeftObjectIDDoesNotExist" 0 "NoError" ;
VAL_ 2632384254 ErrorCodeObjToSize2 0 "NoErrors" 1 "InvalidWidth" ;
VAL_ 2632384254 ErrorCodeChangeNumValue2 0 "NoErrors" 1 "InvalidValue" ;
VAL_ 2632384254 ErrorCodeChangeEditPoint2 0 "NoErrors" 1 "InvalidLineDirection" ;
VAL_ 2632384254 ErrorCodeChangeFont2 0 "NoErrors" 1 "InvalidColour" ;
VAL_ 2632384254 ErrorCodeChangeLineAttribute2 0 "NoErrors" 1 "InvalidObjectColour" ;
VAL_ 2632384254 ErrorCodeChangeFillAttributes2 0 "NoErrors" 1 "InvalidType" ;
VAL_ 2632384254 ErrorCodeChangeActiveMask2 0 "NoErrors" 1 "InvalidMaskObjectID" ;
VAL_ 2632384254 ErrorCodeChangePoygonPoint2 1 "InvalidPointIndex" 0 "NoError" ;
VAL_ 2632384254 ErrorCodeSelectColourMap2 1 "GeneralError" 0 "NoError" ;
VAL_ 2632384254 Hardware2 0 "VT does not report drag operation" 1 "VT reports drag operation" ;
VAL_ 2632384254 ErrorCodeExecuteOpCode2 1 "LeftAIDIsOutOfRange" 0 "NoError" ;
VAL_ 2632384254 ErrorCodeMissingObjects 0 "NoErrors" 1 "MissingObjects" ;
VAL_ 2632384254 ErrorCodeObjToSize3 0 "NoErrors" 1 "InvalidHeight" ;
VAL_ 2632384254 ErrorCodeChangeFont3 0 "NoErrors" 1 "InvalidSize" ;
VAL_ 2632384254 ErrorCodeChangeLineAttribute3 0 "NoErrors" 1 "InvalidWidth" ;
VAL_ 2632384254 ErrorCodeChangeFillAttributes3 0 "NoErrors" 1 "InvalidColour" ;
VAL_ 2632384254 ErrorCodeChangeActiveMask3 0 "NoErrors" 1 "MissingObjects" ;
VAL_ 2632384254 ErrorCodeChangePoygonPoint3 1 "GeneralError" 0 "NoError" ;
VAL_ 2632384254 Hardware3 0 "VT has no multiple frequency audio output" 1 "VT has multiple frequency audio output" ;
VAL_ 2632384254 ErrorCodeExecuteOpCode3 1 "RightObjectIDDoesNotExist" 0 "NoError" ;
VAL_ 2632384254 ErrorCodeChangeNumValue3 0 "NoErrors" 1 "ValueInUse" ;
VAL_ 2632384254 ErrorCodeMaskOrChildObjectError 0 "NoErrors" 1 "MaskOrChildObjectHasErrors" ;
VAL_ 2632384254 ErrorCodeChangeFont4 0 "NoErrors" 1 "InvalidType" ;
VAL_ 2632384254 ErrorCodeChangeFillAttributes4 0 "NoErrors" 1 "InvalidPatternObjectID" ;
VAL_ 2632384254 ErrorCodeChangeActiveMask4 0 "NoErrors" 1 "MaskOrChildObjectHasErrors" ;
VAL_ 2632384254 Hardware4 0 "VT has no adjustable volume audio output" 1 "VT has adjustable volume audio output" ;
VAL_ 2632384254 ErrorCodeExecuteOpCode4 1 "RightAIDIsOutOfRange" 0 "NoError" ;
VAL_ 2632384254 ErrorCodeChangeNumValue4 0 "NoErrors" 1 "ValueInUse" ;
VAL_ 2632384254 ErrorCodeVTEsc2 0 "NoError" 1 "GeneralError" ;
VAL_ 2632384254 ErrorCodeAnyOtherError 0 "NoErrors" 1 "GeneralError" ;
VAL_ 2632384254 ErrorCodeEscapeObj2 0 "NoErrors" 1 "GeneralError" ;
VAL_ 2632384254 ErrorCodeObjToSize4 0 "NoErrors" 1 "GeneralError" ;
VAL_ 2632384254 ErrorCodeExecuteOpCode5 1 "LValueTypeFloatIsNotAllowed" 0 "NoError" ;
VAL_ 2632384254 ErrorCodeChangeEditPoint3 0 "NoErrors" 1 "GeneralError" ;
VAL_ 2632384254 ErrorCodeChangeFont5 0 "NoErrors" 1 "InvalidStyle" ;
VAL_ 2632384254 ErrorCodeChangeLineAttribute4 0 "NoErrors" 1 "GeneralError" ;
VAL_ 2632384254 ErrorCodeChangeFillAttributes5 0 "NoErrors" 1 "GeneralError" ;
VAL_ 2632384254 ErrorCodeChangeActiveMask5 0 "NoErrors" 1 "GeneralError" ;
VAL_ 2632384254 Hardware5 0 "VT does not support simultaneous activations of softkeys" 1 "VT supports simultaneous activations of softkeys" ;
VAL_ 2632384254 ErrorCodePoolDeleted 0 "NoErrors" 1 "PoolBeingDeleted" ;
VAL_ 2632384254 ErrorCodeExecuteOpCode6 1 "NegativeRValueIsNotAllowed" 0 "NoError" ;
VAL_ 2632384254 ManufacturerCode 520 "Trapeze" 519 "Peeters Landbouwmachines b.v." 518 "Transas USA Inc." 517 "Noland Engineering" 516 "AVAT Automation GmbH" 515 "GINAF Trucks Nederland B.V." 514 "DISTek Integration, Inc." 513 "FarmscanAg" 512 "Inpower LLC" 511 "Sulky" 510 "Marinesoft Co. Ltd" 509 "MOTORTECH GmbH" 508 "Transtech Innovations" 507 "Test Center ISOBUS" 506 "IHI STAR Machinery Corporation" 505 "Yetter Farm Equipment" 504 "Vesper Marine" 503 "Naviop S.R.L." 502 "Attwood Corporation" 501 "Agrotronix S.A." 500 "Oxbo International Corporation" 499 "LCJ Capteurs" 498 "Innovative Design Solutions, Inc." 497 "SENTRON Sistemas Embarcados" 496 "W. Gessmann GmbH" 495 "HOLMER Maschinenbau GmbH" 494 "Synerject" 493 "Watcheye" 492 "Inergy Automotive Systems" 491 "Penny and Giles Ltd" 490 "QuikQ" 489 "Appareo Systems" 488 "The Charles Machine Works, Inc." 487 "DSE Test Solutions A/S" 486 "Westport Innovations Inc." 485 "MATT automotive" 484 "Headsight Inc." 483 "Valeo" 482 "Tricon Electronics" 481 "Chetco Digital Instruments" 480 "EnerDel, Inc." 454 "NGK Spark Plug Co. Ltd" 453 "Cooper Bussmann" 452 "WIKA Alexander Wiegand SE & Co. KG" 451 "Parker Hannifin Corp" 450 "Dycor Technologies Ltd." 449 "Polaris Industries Inc" 448 "Stanadyne Corporation, Electronics Systems" 447 "Great Plains Mfg." 446 "CertTech, L.L.C." 445 "KAT MECHATRONIC, Electronic Product Division" 444 "ITT Power Solutions" 443 "SignalQuest, Inc." 442 "Horsch Maschinen GmbH" 441 "PTG Reifendruckregelsysteme GmbH" 440 "Cummins Power Generation" 439 "Hyundai Heavy Industries" 438 "Comar Systems Ltd" 437 "Digital Yacht Limited" 436 "Kinze Manufacturing" 435 "Zunhammer GmbH" 434 "Stored Energy Systems" 433 "Rowe Electronics" 432 "S&A Systems, Inc." 431 "Tohatsu Corporation" 430 "Auteq Telematica S.A." 479 "Vapor Bus International" 478 "OceanSat BV" 477 "OilQuick AB" 476 "Hummingbird Marine Electronics" 475 "GME" 474 "Persen Technologies Inc." 473 "Boss Industries, Inc." 472 "Tenneco Inc." 471 "Sea Cross Marine AB" 470 "SI-TEX Marine Electronics" 469 "RA Consulting GmbH" 468 "Tyco Fire Protection Products" 467 "Lely Industries N.V." 466 "Veethree Electronics and Marine LLC" 465 "Ashcroft Inc" 464 "Leach International Corporation" 463 "PROBOTIQ" 462 "IHI Shibaura Machinery Corporation" 461 "HAWE Hydraulik SE" 460 "San Giorgio S.E.I.N." 459 "Alltek Marine Electronics Corp" 458 "Control Solutions, Inc." 457 "RUSELPROM-ElectricDrive Ltd" 456 "General Kinetics" 455 "ADZ NAGANO GmbH" 429 "Rota Engineering Ltd." 428 "Mfg_428" 427 "em-trak Marine Electronics Ltd" 426 "Egersund Marine Electronics AS" 425 "Methode Electronics Inc, MDI" 424 "Odyne LLC" 423 "BSM Wireless, Inc." 422 "True Heading AB" 421 "Vertex Standard Co., Ltd" 420 "Vermeer Corporation, ACS Group" 419 "Fusion Electronics Ltd" 418 "Intellistick Inc" 417 "KZValve" 416 "Kubota Corporation" 415 "Valid Manufacturing Ltd." 414 "Cattron Group International" 413 "Datapross Nijbroek bv" 412 "WebTech Wireless Inc." 411 "Hy-Drive Technologies Ltd." 410 "COBO S.p.A. Divisione 3B6" 409 "Transfluid S.r.L." 408 "Corvus Energy Ltd." 407 "Comtech Mobile Datacom" 406 "Vecima Networks Inc." 405 "Wema System AS" 404 "Com Nav Marine Ltd" 403 "Trackwell ADS, Inc." 402 "Simma Software, Inc." 401 "Torqeedo GmbH" 400 "Livorsi Marine" 399 "ISEKI & Co., Ltd." 398 "Hilite International" 397 "Sanyo-kiki Co Ltd." 396 "Beyond Measure" 395 "GENTEC S.R.L." 394 "Capi 2 Nederland BV" 393 "Harvest Tec, Inc" 392 "Tianyuan Technology Co Ltd." 391 "Electronic Design for Industry, Inc" 390 "Partech Inc." 389 "Benchmark Electronics, Minnesota Division" 388 "Innomatix, LLC" 387 "Orscheln Products, LLC" 386 "JLG Automation BVBA" 385 "Johnson Outdoor Marine Electronics" 384 "Camano Light" 383 "MCL Industries" 382 "National Agricultural and Food Research Organization" 380 "Suntech International Ltd." 379 "Yamabiko Corporation" 378 "Glendinning Marine Products" 377 "ifm electronic gmbh" 376 "Quake Global" 375 "Williams Controls Inc." 372 "Delphi" 381 "B&G" 374 "Northern Lights, Inc." 373 "Electronic Design Inc." 371 "Heinzmann GmbH & Co. KG" 370 "Rolls-Royce Marine AS" 369 "Power Torque Engineering Ltd" 368 "HANSENHOF_electronic" 367 "Fliegl Agrartechnik" 366 "Viewnyx Corp." 365 "Digi-Star, LLC" 364 "OEM Controls Inc." 363 "BEI Duncan" 362 "Alois Poettinger Maschinenfabrik GmbH" 361 "InMach" 360 "HJS Emission Technology GmbH & Co KG" 359 "Ludwig Bergmann GmbH" 358 "Victron Energy BV" 357 "Hardi International A/S" 356 "Fischer Panda Generators, Inc" 355 "Mastervolt International B.V." 354 "Junkkari OY" 353 "Hegemon Electronics, Inc." 352 "SAME DEUTZ-FAHR" 351 "Thrane & Thrane" 350 "Noris Marine Systems GmbH & Co KG" 349 "Suonentiet" 348 "Amazonen Werke H. Dreyer" 347 "Honeywell" 346 "Control Solutions" 345 "Korean Maritime University" 344 "Parvus Corporation" 343 "Baumer Group" 342 "THOMAS MAGNETE GmbH" 341 "Boning GmbH & Co" 340 "Continental AG" 339 "Competence Center ISOBUS e.V." 338 "GRAF-SYTECO" 337 "Carraro S.p.A." 336 "APE s.r.o." 335 "Evo Electric Ltd" 334 "Takata-Petri AG" 333 "Hadley Products Corporation" 332 "HWH Corporation" 331 "Horton, Inc." 330 "Kidde Aerospace and Defense" 329 "Deif A/S" 328 "Qwerty Electronik AB" 252 "Sensor-Technik Wiedemann GmbH" 251 "German Agricultural Society" 250 "Kuhn Group" 249 "Schaltbau GmbH" 233 "Yacht Monitoring Solutions Inc." 232 "TSD Integrated Controls" 1863 "Thomas G. Faria Co." 1862 "Sanshin" 1861 "Vector CANtech" 1860 "MMP" 1859 "Kvasar AB" 1858 "Litton" 1857 "Simrad" 1856 "Trimble" 1855 "Furuno USA" 1854 "Northstar Technologies" 1853 "Japan Radio Co." 1852 "Navionics" 1851 "Raymarine" 1850 "Teleflex" 222 "Generac Power Systems, Inc." 221 "SiE" 220 "Beede Electrical Instrument Company, Inc." 219 "Cat OEM Solutions" 218 "Gits Manufacturing Company" 217 "RM Michaelides Software & Elektronik GmbH" 216 "Paneltronics Inc." 215 "Aetna Engineering/Fireboy-Xintex" 214 "MC elettronica Srl" 213 "CNH Belgium N.V." 212 "Sure Power Industries, Inc." 211 "DNA Group" 210 "Iteris, Inc." 209 "Bell Equip. Co. SA (PTY) LTD" 208 "Drew Technologies, Inc." 207 "Otto Engineering" 206 "port GmbH" 205 "SmarTire Systems Inc" 204 "The Morey Corporation" 203 "MILtronik GmbH" 202 "Curtis Instruments, Inc." 201 "Disenos y Tecnologia S.A." 200 "MGM Brakes" 199 "Actia Corp." 198 "Mystic Valley Communications" 197 "Mechron Power Systems" 196 "LEMKEN GmbH & Co. KG" 195 "General Engine Products" 194 "TriMark Corporation" 193 "Nobletec" 192 "Floscan" 191 "XRS Corporation" 190 "Hella KGaA Hueck & Co." 189 "QUALCOMM" 188 "EMP Corp." 187 "Air-Weigh" 186 "Altronic, Inc." 185 "Beede Electrical Instrument Company" 184 "EIA Electronics" 183 "KDS Controls, Inc." 182 "Vehicle Systems Engineering B.V." 181 "Coretronics, Inc." 180 "Smart Power Systems" 179 "TeeJet Technologies Denmark" 178 "Siemens VDO Automotive AG" 177 "Diagnostic System Associates" 176 "Moritz Aerospace" 175 "Veris Technologies, Inc." 174 "AB Volvo Penta" 173 "Ryeso, Inc." 172 "Yanmar Marine USA" 171 "Wachendorff Elektronik GmbH & Co. KG" 170 "Computronics Corporation Ltd." 169 "Marlin Technologies Inc." 168 "Xantrex" 167 "JLG Industries Inc." 166 "Phoenix International" 165 "CPAC Systems AB" 164 "DaimlerChrysler Off-Highway" 163 "BRP Inc." 162 "Axiomatic Technologies" 161 "Offshore Systems (UK) Limited" 160 "Nido" 159 "NTech Industries Inc." 158 "Firestone Industrial Products Company" 157 "ISSPRO Inc." 156 "ITT Industries - Cannon" 155 "Vetronix Corporation" 154 "Westerbeke Corporation" 153 "Woodward, Industrial Controls Division" 152 "elobau GmbH & Co. KG" 151 "Raven Industries Inc. - Flow Controls Division" 150 "Fleetguard" 149 "Holset" 148 "Blue Water Data, Inc." 147 "Nautibus Electronic GmbH" 146 "Maxima Technologies" 145 "MurCal Controls" 144 "Mercury Marine" 143 "W. Gmeiner GmbH & Co." 142 "TRW Automotive (Commercial Steering Systems)" 141 "Thales Navigation Ltd." 140 "Lowrance Electronics, Inc." 139 "Caterpillar Trimble Control Technologies (CTCT), LLC" 138 "Georg Fritzmeier GmbH & Co. KG" 137 "Maretron" 136 "Komatsu Ltd." 135 "Airmar Technology Corporation" 134 "Iris Technology Ltd." 133 "Bucher Schoerling GmbH" 132 "Mulag-Fahrzeugwerk" 131 "ITT Industries" 130 "Nido - Universal Machines B.V." 129 "OMNEX Control Systems, Inc." 128 "Gerhard Duecker GmbH & Co. KG" 127 "Holland USA" 126 "Driver Tech" 125 "Nevada Automotive Test Center" 124 "Hydac Electronic" 123 "Basler Electric" 122 "FG Wilson (Engineering) Limited" 121 "HED (Hydro Electronic Devices, Inc.)" 120 "RDS Technology Ltd." 119 "IntegriNautics" 118 "Intron GmbH" 117 "HUSCO International" 116 "BEELINE Technologies" 115 "NACCO Materials Handling Group, Inc." 114 "EControls, Inc." 113 "Stress-Tek, Inc." 112 "MECALAC" 111 "Maschinenfabrik Bernard Krone GmbH" 110 "EPIQ Sensor-Nite" 109 "TeeJet Technologies Denmark" 108 "WTK-Elecktronik GmbH" 107 "Grimme Landmaschinen GmbH & Co. KG" 106 "BAE Systems Controls, Inc." 105 "Kiepe Elektrik GmbH & Co. KG" 104 "Claas Selbstfahrende Erntemaschinen GmbH" 103 "CLAAS Agrosystems GmbH & Co. KG" 102 "AGCO GmbH & Co." 101 "Sensoria" 100 "VDO Technik AG" 99 "International Transmissions Ltd (ITL)" 98 "Mueller-Elektronik GmbH & Co." 97 "Ag Leader Technology, Inc." 96 "Mech@tronic IT GmbH" 95 "Pacific Insight Electronics Corp." 94 "CNH Global N.V." 93 "Perkins Engines Company Ltd." 92 "Ag-Chem Equipment Co., Inc." 91 "BSG Bodensee Steuergeraete GmbH" 90 "Knorr-Bremse SfN GmbH" 89 "Kverneland Group, Electronics Division" 88 "Satloc Precision GPS" 87 "J.C. Bamford Excavators Ltd (JCB)" 86 "C.E. Niehoff & Company" 85 "Kohler Co." 84 "New Holland UK Limited" 83 "Bendix VORAD Technologies" 82 "Bobcat/Ingersoll-Rand" 81 "Fire Research Corp" 80 "Twin Disc, Inc." 79 "Daimler Benz AG - Engine Division (PBM)" 78 "Frank W. Murphy Manufacturing, Inc." 77 "Deere Power Systems Group" 76 "unused" 75 "Deere & Co. Agricultural Division" 74 "Eaton Axle-Brake Division" 73 "LeTourneau, Inc." 72 "Sisu Corporation" 71 "Vansco Electronics Ltd." 70 "Flex-Coil Limited" 69 "Trimble Navigation" 68 "Scania" 67 "Funk Manufacturing Company" 66 "John Deere Construction Equipment Division" 65 "MAN Nutzfahrzeuge AG" 64 "unused" 63 "ZF Industries Inc." 62 "Wabco" 61 "Volvo Truck Corp." 60 "Volvo Trucks North America Inc." 59 "VES Inc." 58 "SPX Corporation, OTC Division" 57 "Sauer-Danfoss Co." 56 "SAIC" 55 "Ryder System Inc." 54 "Meritor Wabco" 53 "Continental Automotive Systems US, Inc." 52 "Meritor Automotive, Inc." 51 "Robert Bosch GmbH" 50 "Robert Bosch Corp" 49 "RE America Inc." 48 "Pollak Alphabet" 47 "Phillips Semiconductor" 46 "Noregon Systems, Inc" 45 "PACCAR" 44 "Nippondenso Co. Ltd." 43 "International Truck and Engine Corp. Vehicle Electronics" 42 "International Truck and Engine Corp. Engine Electronics" 41 "Motorola Inc." 40 "Motorola AIEG Inc." 39 "Microfirm Inc." 38 "Micro Processor Systems Inc." 37 "Mack Trucks Inc." 36 "Lucas Ltd." 35 "Kenworth Truck Co." 34 "Kelsey Hayes Co." 33 "John Deere" 32 "Jacobs Vehicle Systems" 31 "J Pollak Corp." 30 "Isuzu Motors Ltd." 29 "Hino Motors Ltd." 28 "Grote Ind. Inc." 27 "GMC" 26 "General Motors Corp., Service Technology Group" 25 "Daimler Trucks North America LLC" 24 "Ford Motor Co., Vehicle Controls" 23 "Ford Motor Co., Heavy Truck" 22 "Ford Motor Co., Electronic Concepts $ Systems" 21 "Echilin Inc., Midland Brake Inc." 20 "Eaton Ltd" 19 "Eaton Corp. Trucking Info Services" 18 "Eaton Corp, Transmission Division" 17 "Eaton Corp. Res & Dev" 16 "Eaton Corp." 15 "Dickey-John Corp." 14 "Detroit Diesel Corporation" 13 "Delco Electronics" 12 "Deere & Company, Precision Farming" 11 "Dearborn Group Inc." 10 "Cummins Engine Co." 9 "Chrysler Corp." 8 "Caterpillar Inc." 7 "Case Corp." 6 "Berifors Electronics AB" 5 "AMP Inc." 4 "Ametek-Dixson" 3 "Ametek, US Gauge Division" 2 "Allison Transmission, GMC" 1 "Allied Signal Inc." 0 "Reserved" 231 "Topcon Positioning Systems, Inc." 230 "Saucon Technologies" 229 "Garmin International Inc." 228 "ZF Marine Electronics" 227 "Lykketronic A/S" 226 "Monaco Coach Corporation" 225 "SKF" 224 "EMMI Network, S.L." 223 "Vaueo Retarder Co., Ltd." 263 "IMMI" 262 "HydraForce, Inc" 261 "Red Dot Corporation" 260 "Reichhardt GmbH" 259 "Jetter AG" 258 "ARAG" 257 "Honda Motor Co., Ltd" 256 "Tyco Electronics AMP" 255 "MEAS France" 254 "GE Sensing" 253 "Mobile Control Systems" 298 "Holley Performance" 297 "Zonar Systems Inc" 296 "micro dynamics GmbH" 295 "BEP Marine" 294 "Grayhill Inc." 293 "Spyder Controls Corp." 292 "IKUSI - Angel Iglesias S.A." 291 "Groeneveld Transport Efficiency BV" 290 "Kuebler GmbH" 289 "Watlow" 288 "Mitsubishi FUSO Truck & Bus Corp." 287 "NTech Industries, Inc" 286 "Coelmo srl" 285 "Sea Recovery Corp" 284 "Mobile Tech Chile" 283 "CWF Hamilton & Co Ltd" 282 "Medallion Instrumentation Systems" 281 "Precision Governors LLC" 311 "Patrick Power Products" 310 "TECNORD srl" 309 "Krauss-Maffei Wegmann GmbH & Co. KG" 308 "Cyntrx" 307 "MBW Technologies" 306 "Sleipner Motor AB" 305 "NovAtel Inc" 304 "EmpirBus AB" 303 "CTS Corporation" 302 "Nissin Kogyo Co., LTD" 301 "Parker Hannifin (UK) Ltd FDE group" 300 "Systron Donner Automotive" 299 "Rauch Landmaschinen GmbH" 280 "Leica Geosystems Pty Ltd" 279 "Geometris LP" 278 "Takata Electronics" 277 "LHP Telematics" 276 "Aqua-Hot Heating Systems" 275 "Navico Egersund AS" 274 "LTW Technology Co., LTD" 273 "Active Research Limited" 272 "Gross Mechanical Laboratories, Inc" 327 "Sonceboz SA" 326 "Akron Brass Company" 325 "ASM Automation Sensorik Messtechnik GmbH" 324 "Snap-on Diagnostics" 323 "Mobileye Vision Technologies Ltd." 322 "MICHENKA s.r.o." 321 "Ultra Electronics, Electrics" 320 "Miedema Landbouwwerktuigenfabriek B.V." 319 "Cadec Global" 318 "SAT Plan" 317 "Navtronics Bvba" 316 "ITT Flow Control" 315 "Icom Incorporated" 314 "CSM GmbH" 313 "Ilmor Engineering, Inc" 312 "Lectronix, Inc." 271 "Cole Hersee" 270 "Tennant" 269 "Saft America Inc.,  Space & Defense Division" 268 "Accurate Technologies" 267 "Red Lion Controls, Inc" 266 "International Thermal Research Ltd" 265 "MTS Sensor Technologie GmbH" 264 "Autolync" 248 "Cooper Standard Automotive Active Systems Group" 247 "ePULSE" 246 "Class 1, Inc" 245 "Capstan Ag Systems, Inc." 244 "Techno-Matic" 243 "eRide, Inc." 242 "Kokusandenki Co. Ltd" 241 "Schneider Automation SAS " 240 "Vanair Mfg" 239 "May & Scofield Ltd" 238 "ZF Friedrichshafen AG" 237 "Agtron Enterprises Inc" 236 "Norac Systems International Inc" 235 "SailorMade Marine Telemetry - Tetra Technology Ltd." 234 "Mondial electronic GmbH" ;
VAL_ 2632384254 ErrorCodeChangeFont6 0 "NoErrors" 1 "GeneralError" ;
VAL_ 2632384254 Hardware6 0 "VT does not support intermediate coordinates during a drag operation" 1 "VT supports intermediate coordinates during a drag operation" ;
VAL_ 2632384254 ErrorCodeExecuteOpCode7 1 "GeneralError" 0 "NoError" ;
VAL_ 2632384254 KeyObjectParentID 0 "KeyHasBeenReleased" 1 "KeyHasBeenPressed" 2 "KeyIsStillHeld" ;
VAL_ 2632384254 ButtonObjectParentID 0 "ButtonHasBeenUnlatched" 1 "ButtonHasBeenLatched" 2 "ButtonsStillHeld" ;
VAL_ 2632384254 VTSelectInputObjectIsEdited 0 "ObjectIsNotEdited" 1 "ObjectIsOpenForEditing" ;
VAL_ 2632384254 ErrorCodeHideShowObj1 0 "NoErrors" 1 "ReferencesToMissingObjects" ;
VAL_ 2632384254 ErrorCodeSelectObject1 1 "ObjectIsDisabled" 0 "NoErrors" ;
VAL_ 2632384254 ErrorCodeChangeColour1 0 "NoErrors" 1 "InvalidObjectID" ;
VAL_ 2632384254 ErrorCodeChangeAttribute1 0 "NoErrors" 1 "InvalidObjectID" ;
VAL_ 2632384254 ErrorCodeChangePriority1 0 "NoErrors" 1 "InvalidObjectID" ;
VAL_ 2632384254 ErrorCodeGraphicsContextCmd1 1 "InvalidObjectID" 0 "NoError" ;
VAL_ 2632384254 ErrorCodeHideShowObj2 0 "NoErrors" 1 "InvalidObjectID" ;
VAL_ 2632384254 ErrorCodeEnableDisableObj1 0 "NoErrors" 1 "InvalidObjectID" ;
VAL_ 2632384254 ErrorCodeSelectObject2 0 "NoErrors" 1 "InvalidObjectID" ;
VAL_ 2632384254 ErrorCodeChangeColour2 0 "NoErrors" 1 "InvalidColourCode" ;
VAL_ 2632384254 ErrorCodeChangeAttribute2 0 "NoErrors" 1 "InvalidAttributeID" ;
VAL_ 2632384254 ErrorCodeChangePriority2 0 "NoErrors" 1 "InvalidPriority" ;
VAL_ 2632384254 ErrorCodeGraphicsContextCmd2 1 "InvalidCommandID" 0 "NoError" ;
VAL_ 2632384254 ErrorCodeEnableDisableObj2 0 "NoErrors" 1 "CommandError" ;
VAL_ 2632384254 ErrorCodeSelectObject3 0 "NoErrors" 1 "ObjectIsNotVisible" ;
VAL_ 2632384254 ErrorCodeChangeAttribute3 0 "NoErrors" 1 "InvalidValue" ;
VAL_ 2632384254 ErrorCodeGraphicsContextCmd3 1 "InvalidParameter" 0 "NoError" ;
VAL_ 2632384254 ErrorCodeHideShowObj3 0 "NoErrors" 1 "GeneralError" ;
VAL_ 2632384254 ErrorCodeEnableDisableObj3 1 "Could not complete. Operator inp" 0 "NoErrors" ;
VAL_ 2632384254 ErrorCodeSelectObject4 0 "NoErrors" 1 "CouldNotComplete" ;
VAL_ 2632384254 ErrorCodeGraphicsContextCmd4 1 "CommandWillProduceInvalidResults" 0 "NoError" ;
VAL_ 2632384254 ErrorCodeEnableDisableObj4 0 "NoErrors" 1 "GeneralError" ;
VAL_ 2632384254 ErrorCodeSelectObject5 0 "NoErrors" 1 "GeneralError" ;
VAL_ 2632384254 ErrorCodeChangeColour3 0 "NoErrors" 1 "GeneralError" ;
VAL_ 2632384254 ErrorCodeChangeAttribute4 0 "NoErrors" 1 "ValueInUse" ;
VAL_ 2632384254 ErrorCodeChangePriority3 0 "NoErrors" 1 "GeneralError" ;
VAL_ 2632384254 ErrorCodeGraphicsContextCmd5 1 "GeneralError" 0 "NoError" ;
VAL_ 2632384254 ErrorCodeSelectObject6 0 "NoErrors" 1 "InvalidOptionValue" ;
VAL_ 2632384254 ErrorCodeVTChangeSoftKeyMask1 0 "NoError" 1 "InvalidDataOrAlarmMaskObjectID" ;
VAL_ 2632384254 TouchState 255 "Pressed" 2 "Held" 1 "Pressed" 0 "Released" ;
VAL_ 2632384254 ErrorCodeChangeChildLocation1 0 "NoErrors" 1 "InvalidParentObjectID" ;
VAL_ 2632384254 ErrorCodeChangeSoftKeyMask1 0 "NoErrors" 1 "InvalidDataOrAlarmMaskObjectID" ;
VAL_ 2632384254 ErrorCodeChangePosInvalidParent 0 "NoErrors" 1 "InvalidParentObjectID" ;
VAL_ 2632384254 FontSize_8x8 0 "NotSupported" 1 "Supported" ;
VAL_ 2632384254 AcknowledgmentStoreVersion 0 "SuccessfullyStored" 2 "VersionLabelIsNotCorrect" 4 "InsufficientMemoryAvailable" 8 "GeneralError" ;
VAL_ 2632384254 AcknowledgmentLoadVersion 0 "SuccessfullyLoaded" 2 "VersionLabelNotCorrectOrUnknown" 4 "InsufficientMemoryAvailable" 8 "GeneralError" ;
VAL_ 2632384254 AcknowledgmentDeleteVersion 0 "SuccessfullyDeleted" 2 "VersionLabelIsNotCorrect" 4 "NA" 8 "GeneralError" ;
VAL_ 2632384254 ErrorCodeVtObjPoolError1 0 "NoErrors" 1 "UnsupportedMethodOrAttribute" ;
VAL_ 2632384254 ErrorCodeVTChangeSoftKeyMask2 0 "NoError" 1 "InvalidSoftKeyMaskObjectID" ;
VAL_ 2632384254 ErrorCodeChangeChildLocation2 0 "NoErrors" 1 "InvalidObjectID" ;
VAL_ 2632384254 ErrorCodeChangeSoftKeyMask2 0 "NoErrors" 1 "InvalidSoftKeyMaskObjectID" ;
VAL_ 2632384254 ErrorCodeChangeStrObjectID 0 "NoErrors" 1 "InvalidObjectID" ;
VAL_ 2632384254 ErrorCodeChangePosInvalidObject 0 "NoErrors" 1 "InvalidObjectID" ;
VAL_ 2632384254 FontSize_8x12 0 "NotSupported" 1 "Supported" ;
VAL_ 2632384254 ErrorCodeVtObjPoolError2 0 "NoErrors" 1 "UnknownObjectReference" ;
VAL_ 2632384254 ErrorCodeVTChangeSoftKeyMask3 0 "NoError" 1 "MissingObjects" ;
VAL_ 2632384254 ErrorCodeChangeSoftKeyMask3 0 "NoErrors" 1 "Missing Objects" ;
VAL_ 2632384254 ErrorCodeChangeStrTooLong 0 "NoErrors" 1 "StringTooLong" ;
VAL_ 2632384254 FontSize_12x16 0 "NotSupported" 1 "Supported" ;
VAL_ 2632384254 ErrorCodeVtObjPoolError3 0 "NoErrors" 1 "RecursiveObjectReference" ;
VAL_ 2632384254 ErrorCodeVTChangeSoftKeyMask4 0 "NoError" 1 "MaskOrChildObjectHasErrors" ;
VAL_ 2632384254 ErrorCodeChangeSoftKeyMask4 0 "NoErrors" 1 "Mask or child object has errors" ;
VAL_ 2632384254 ErrorCodeChangeStrError 0 "NoErrors" 1 "GeneralError" ;
VAL_ 2632384254 FontSize_16x16 0 "NotSupported" 1 "Supported" ;
VAL_ 2632384254 ErrorCodeVtObjPoolError4 0 "NoErrors" 1 "OtherError" ;
VAL_ 2632384254 ErrorCodeChangeStrValueInUse 0 "NoErrors" 1 "ValueInUse" ;
VAL_ 2632384254 ErrorCodeVTChangeSoftKeyMask5 0 "NoError" 1 "GeneralError" ;
VAL_ 2632384254 ErrorCodeChangeChildLocation5 0 "NoErrors" 1 "GeneralError" ;
VAL_ 2632384254 ErrorCodeChangeSoftKeyMask5 0 "NoErrors" 1 "GeneralError" ;
VAL_ 2632384254 ErrorCodeChangePosInvalidError 0 "NoErrors" 1 "GeneralError" ;
VAL_ 2632384254 FontSize_16x24 0 "NotSupported" 1 "Supported" ;
VAL_ 2632384254 FontSize_24x32 0 "NotSupported" 1 "Supported" ;
VAL_ 2632384254 FontSize_32x32 0 "NotSupported" 1 "Supported" ;
VAL_ 2632384254 Status_2 1 "Shown" 0 "Hidden" ;
VAL_ 2632384254 BooleanValue 2 "EnabledStillHeld" 1 "Enabled" 0 "Disabled" ;
VAL_ 2632384254 SoftKeyCode 0 "AlarmACK" ;
VAL_ 2632384254 ErrorCodeObjectPool1 0 "NoErrors" 1 "MethodOrAttributeNotSupportedByV" ;
VAL_ 2632384254 Function 127 "Reserved" 126 "Reserved" 125 "Reserved" 124 "Reserved" 123 "Reserved" 122 "Reserved" 121 "Reserved" 120 "Reserved" 119 "Reserved" 118 "Reserved" 117 "Reserved" 116 "Reserved" 115 "Reserved" 114 "Reserved" 113 "Reserved" 112 "Reserved" 111 "Reserved" 110 "Reserved" 109 "Reserved" 108 "Reserved" 107 "Reserved" 106 "Reserved" 105 "Reserved" 104 "Reserved" 103 "Reserved" 102 "Reserved" 101 "Reserved" 42 "Water Pump Control" 41 "Lighting - Operator Controls" 40 "Seat Control" 39 "Ignition Control Module" 38 "Tire Pressure Control" 37 "Cab Controller" 36 "Pneumatic - System Controller" 35 "Suspension - System Controller" 34 "Hydraulic Pump Controller" 33 "System Monitor" 32 "Headway Controller" 31 "Propulsion Battery Charger" 30 "Management Computer" 29 "Virtual Terminal (in cab)" 28 "Off Vehicle Gateway" 27 "Power TakeOff (Secondary or Front)" 26 "Body Controller" 25 "Network Interconnect ECU" 24 "Vehicle Security" 23 "Vehicle Navigation" 22 "Aerodynamic Control" 21 "Cab Climate Control" 20 "Trip Recorder" 19 "Instrument Cluster" 18 "Suspension - Drive Axle" 17 "Suspension - Steer Axle" 16 "Steering Controller" 15 "Fuel System" 14 "Cruise Control" 13 "Retarder - Driveline" 12 "Retarder - Engine" 11 "Brakes - Drive Axle" 10 "Brakes - Steer Axle" 9 "Brakes - System Controller" 8 "Axle - Drive" 7 "Axle - Steering" 6 "Power TakeOff - (Main or Rear)" 5 "Shift Control/Console" 4 "Battery Pack Monitor" 3 "Transmission" 2 "Electric Propulsion Control" 1 "Auxiliary Power Unit (APU)" 0 "Engine" 100 "Reserved" 99 "Reserved" 98 "Reserved" 97 "Reserved" 96 "Reserved" 95 "Reserved" 94 "Reserved" 93 "Reserved" 92 "Reserved" 91 "Reserved" 90 "Reserved" 89 "Reserved" 88 "Reserved" 87 "Reserved" 86 "Reserved" 85 "Reserved" 84 "Reserved" 83 "Reserved" 82 "Reserved" 81 "Reserved" 80 "Reserved" 79 "Reserved" 78 "Fire Suppression System" 77 "Fuel Properties Sensor" 76 "Temperature Sensor" 75 "Supplemental Fan" 74 "Lubrication System" 73 "Rollover Detection Control" 72 "Coolant Valve Controller" 71 "Transfer Case Control" 70 "Auxiliary Regeneration Device" 69 "Engine Emission Aftertreatement System" 68 "Aftertreatment system gas measurement" 67 "Electrical System Controller" 66 "I/O Controller" 65 "Gas Flow Measurement" 64 "Endurance Braking" 63 "Engine Valve Controller" 62 "On-Board Diagnostic Unit" 61 "File Server/Printer" 60 "Cab Display" 59 "Starter" 58 "Fan Drive Control" 57 "Steering Column Unit" 56 "Communications Unit, Radio" 55 "Communications Unit, Satellite" 54 "Communications Unit, Cellular" 53 "Alternator/Charging System" 52 "Chassis Controller" 51 "Forward-Looking Collision Warning System" 50 "Auxiliary Heater" 49 "Clutch/Converter Control" 48 "Ramp Control" 47 "Information System Controller" 46 "Oil Sensor Unit" 45 "Vehicle Dynamic Stability Control" 44 "Exhaust Emission Control" 43 "Transmission Display" ;
VAL_ 2632384254 ErrorCodeChangeListItem1 0 "NoErrors" 1 "InvalidListObjectID" ;
VAL_ 2632384254 ErrorCodeGetSupportedWideChars1 1 "TooManyRanges" 0 "NoError" ;
VAL_ 2632384254 FontSize_32x48 0 "NotSupported" 1 "Supported" ;
VAL_ 2632384254 VTBusyCode1 1 "VTIsBusyUpdatingVisibleMask" ;
VAL_ 2632384254 ErrorCodeObjectPool2 0 "NoErrors" 1 "UnknownObjectReference" ;
VAL_ 2632384254 ErrorCodeChangeListItem2 0 "NoErrors" 1 "InvalidListIndex" ;
VAL_ 2632384254 FontSize_48x64 0 "NotSupported" 1 "Supported" ;
VAL_ 2632384254 VTBusyCode2 1 "VTIsBusySavingDataToNonVolMemory" ;
VAL_ 2632384254 ErrorCodeObjectPool3 0 "NoErrors" 1 "GeneralError" ;
VAL_ 2632384254 ErrorCodeChangeListItem3 0 "NoErrors" 1 "InvalidNewListItemObjectID" ;
VAL_ 2632384254 FontSize_64x64 0 "NotSupported" 1 "Supported" ;
VAL_ 2632384254 VTBusyCode3 1 "VTIsBusyExecutingCommand" ;
VAL_ 2632384254 ErrorCodeObjectPool4 0 "NoErrors" 1 "ObjectPoolWasDeletedFromVolatile" ;
VAL_ 2632384254 FontSize_64x96 0 "NotSupported" 1 "Supported" ;
VAL_ 2632384254 VTBusyCode4 1 "VTIsBusyExecutingMacro" ;
VAL_ 2632384254 ErrorCodeChangeListItem4 0 "NoErrors" 1 "ValueInUse" ;
VAL_ 2632384254 ErrorCodeChangeListItem5 0 "NoErrors" 1 "ValueInUse" ;
VAL_ 2632384254 ErrorCodeGetSupportedWideChars2 1 "GeneralError" 0 "NoError" ;
VAL_ 2632384254 FontSize_96x128 0 "NotSupported" 1 "Supported" ;
VAL_ 2632384254 VTBusyCode5 1 "VTIsBusyParsingAnObjectPool" ;
VAL_ 2632384254 FontSize_128x128 0 "NotSupported" 1 "Supported" ;
VAL_ 2632384254 VTBusyCode7 1 "AuxiliaryControlsLearnModeActive" ;
VAL_ 2632384254 FontSize_128x192 0 "NotSupported" 1 "Supported" ;
VAL_ 2632384254 VTBusyCode8 1 "VTIsOutOfMemory" ;
VAL_ 2632384254 OperatingState1 1 "LearnModeActive" 0 "LearnModeInactive" ;
VAL_ 2632384254 ErrorCodeChangePolygonScale1 1 "InvalidObjectId" 0 "NoError" ;
VAL_ 2632384254 FontType_BoldText 0 "NotSupported" 1 "Supported" ;
VAL_ 2632384254 OperatingState2 1 "InputActivatedInLearnMode" 0 "InputNotActivatedInLearnMode" ;
VAL_ 2632384254 FontType_CrossedOutText 0 "NotSupported" 1 "Supported" ;
VAL_ 2632384254 FontType_UnderlinedText 0 "NotSupported" 1 "Supported" ;
VAL_ 2632384254 FontType_ItalicsText 0 "NotSupported" 1 "Supported" ;
VAL_ 2632384254 ErrorCodeChangePolygonScale5 1 "GeneralError" 0 "NoError" ;
VAL_ 2632384254 FontType_InvertedText 0 "NotSupported" 1 "Supported" ;
VAL_ 2632384254 FontType_FlashInverted 0 "NotSupported" 1 "Supported" ;
VAL_ 2632384254 FontType_FlashHidden 0 "NotSupported" 1 "Supported" ;
VAL_ 2632384254 FontType_ProportionalFont 0 "NotSupported" 1 "Supported" ;
VAL_ 2632384254 IndustryGroup 6 "Reserved for SAE" 0 "Global" 1 "On-Highway" 2 "Agricultural and Forestry" 3 "Construction" 4 "Marine" 5 "IndustrialProcessCtrlStationary" 7 "Reserved for SAE" ;
VAL_ 2632384254 ErrorCodeChangeAttribute5 0 "NoErrors" 1 "GeneralError" ;
VAL_ 2632384254 StoreAsPreferredAssignment 1 "DoNotStoreAssignment" 0 "StoreAssignment" ;
VAL_ 2632384254 AssignedAttribute1OfSet1 1 "AuxiliaryFunction" 0 "AuxiliaryInput" ;
VAL_ 2632384254 AssignedAttribute2OfSet1 1 "InputIsAssigned" ;
VAL_ 2365458942 SpeedInfo_EngineSpeed 0 "EngineSpeedInfoNotAvailable" 1 "EngineSpeedInfoAvailable" ;
VAL_ 2365458942 SpeedInfo_GroundBasedSpeed 0 "GndBasedSpeedInfoNotAvailable" 1 "GndBasedSpeedInfoAvailable" ;
VAL_ 2365458942 SpeedInfo_WheelBasedSpeed 0 "WheelBasedSpeedInfoNotAvailable" 1 "WheelBasedSpeedInfoAvailable" ;
VAL_ 2365458942 PowerMgt_MaintainPower 0 "MainPwrMgtNotAvailable" 1 "MainPwrMgtAvailable" ;
VAL_ 2365458942 PowerMgt_MaxTimeTractorPower 0 "MaxTimeTractorPwrMgtNotAvailable" 1 "MaxTimeTractorPwrMgtAvailable" ;
VAL_ 2365458942 PowerMgt_KeySwitch 0 "KeySwitchPwrMgtNotAvailable" 1 "KeySwitchPwrMgtAvailable" ;
VAL_ 2365458942 TractorClass 0 "TECU_Class_1" 1 "TECU_Class_2" 2 "TECU_Class_3" 3 "NotAvailable" ;
VAL_ 2365458942 LanguageCmdStorageInTractorECU 0 "LangCmdNotAvailableInTractorECU" 1 "LangCmdAvailableInTractorECU" ;
VAL_ 2365458942 Lighting_MinimalSet 0 "MinSetNotAvailable" 1 "MinSetAvailable" ;
VAL_ 2365458942 PTOInfo_RearShaftEngagement 0 "PTOInfo_RearShaftEgtNotAvailable" 1 "PTOInfo_RearShaftEgtAvailable" ;
VAL_ 2365458942 PTOInfo_RearShaftSpeed 0 "PTOInfo_RearShaftSpdNotAvailable" 1 "PTOInfo_RearShaftSpdAvailable" ;
VAL_ 2365458942 HitchInfo_RearInWork 0 "HitchInfo_RearInWorkNotAvailable" 1 "HitchInfo_RearInWorkAvailable" ;
VAL_ 2365458942 HitchInfo_RearPosition 0 "HitchInfo_RearInPosNotAvailable" 1 "HitchInfo_RearInPosAvailable" ;
VAL_ 2365458942 EstimatedOrMeasuredAuxValveState 0 "EstOrMeasAuxValStatNotAvailable" 1 "EstOrMeasAuxValStatAvailable" ;
VAL_ 2365458942 Light_FullImplLightingMessageSet 0 "FullImplLightMsgSetNotAvailable" 1 "FullImplLightMsgSetAvailable" ;
VAL_ 2365458942 AddHitchParameter_RearDraft 0 "HitchInfo_RearDraftNotAvailable" 1 "HitchInfo_RearDraftAvailable" ;
VAL_ 2365458942 SpeedAndDist_WheelBasedDirection 0 "WheelBasedDirectionNotAvailable" 1 "WheelBasedDirectionAvailable" ;
VAL_ 2365458942 SpeedAndDist_WheelBasedDistance 0 "WheelBasedDistanceNotAvailable" 1 "WheelBasedDistanceAvailable" ;
VAL_ 2365458942 SpeedAndDist_GndBasedDirection 0 "GndBasedDirectionNotAvailable" 1 "GndBasedDirectionAvailable" ;
VAL_ 2365458942 SpeedAndDist_GndBasedDistance 0 "GndBasedDistanceNotAvailable" 1 "GndBasedDistanceAvailable" ;
VAL_ 2365458942 TimeDate 0 "TimeAndDateNotAvailable" 1 "TimeAndDateAvailable" ;
VAL_ 2365458942 LimitStatusReporting 1 "Facility available" 0 "Facility not available" ;
VAL_ 2365458942 AuxiliaryValveCmd 0 "AuxiliaryValveCmdsNotAvailable" 1 "AuxiliaryValveCmdsAvailable" ;
VAL_ 2365458942 PTOCmd_RearPTOEngagementCmd 0 "RearPTOEgtCmdNotAvailable" 1 "RearPTOEgtCmdAvailable" ;
VAL_ 2365458942 PTOCmd_RearPTOSpeedCmd 0 "RearPTOSpeedCmdNotAvailable" 1 "RearPTOSpeedCmdAvailable" ;
VAL_ 2365458942 HitchCmd_RearHitchPosition 0 "HitchRearPosNotAvailable" 1 "HitchRearPosAvailable" ;
VAL_ 2365458942 NavigPseudorangeNoiseStatistic 0 "NavigPsdoNoiseStatNotAvailable" 1 "NavigPsdoNoiseStatAvailable" ;
VAL_ 2365458942 NavigSystemPositionData 0 "NavigSysPosDataNotAvailable" 1 "NavigSysPosDataAvailable" ;
VAL_ 2365458942 NavigSystemHighOutputPosition 0 "NavigSysHOutPosDataNotAvailable" 1 "NavigSysHOutPosDataAvailable" ;
VAL_ 2365458942 PTOCmd_FrontPTOEngagementCmd 0 "FrontPTOEgtCmdNotAvailable" 1 "FrontPTOEgtCmdAvailable" ;
VAL_ 2365458942 PTOCmd_FrontPTOSpeedCmd 0 "FrontPTOSpeedCmdNotAvailable" 1 "FrontPTOSpeedCmdAvailable" ;
VAL_ 2365458942 HitchCmd_FrontHitchPosition 0 "FrontHitchPosNotAvailable" 1 "FrontHitchPosAvailable" ;
VAL_ 2365458942 AddHitchParameter__FrontDraft 0 "FrontDraftNotAvailable" 1 "FrontDraftAvailable" ;
VAL_ 2365458942 PTOInfo_FrontShaftEngagement 0 "FrontShaftEgtNotAvailable" 1 "FrontShaftEgtAvailable" ;
VAL_ 2365458942 PTOInfo_FrontShaftSpeed 0 "FrontShaftSpeedNotAvailable" 1 "FrontShaftSpeedAvailable" ;
VAL_ 2365458942 HitchInfo_FrontInWork 0 "FrontInWorkNotAvailable" 1 "FrontInWorkAvailable" ;
VAL_ 2365458942 HitchInfo_FrontPosition 0 "FrontPositionNotAvailable" 1 "FrontPositionAvailable" ;
VAL_ 2358181630 MessageCode 149 "SCMasterStatus" 145 "SCMasterMemoryResponse" 144 "SCMasterCapablilityResponse" 53 "SCClientFunctionErrorRequest" 52 "SCClientExecutionAcknowledgement" 51 "SCMasterExecutionCommand" 50 "SCExecutionIndicationResponse" 48 "SCStateCommand" 7 "SCDLoadResponse" 6 "SCDStoreResponse" 5 "SCDDeleteResponse" 4 "SCDActivationResponse" 3 "SCDTransferResponse" 2 "SCDConfigurationLabelResponse" 1 "SCDVersionResponse" ;
VAL_ 2358181630 LoadResponseError 255 "GeneralError" 3 "NotEnoughVolatileMemoryAvailable" 2 "FileSystemErrorOrDataCorruption" 1 "SCDNotFound" 0 "NoError" ;
VAL_ 2358181630 StoreCommandError 255 "GeneralError" 2 "NotEnoughNonVolatileMemory" 1 "SCDWasNotCompletelyParsed" 0 "NoError" ;
VAL_ 2358181630 DeleteCommandResponseError 255 "GeneralError" 1 "SCDDoesNotExist" 0 "NoError" ;
VAL_ 2358181630 CommandedSCCState 1 "Enabled" 0 "Disabled" ;
VAL_ 2358181630 SCVersion 2 "IS" 1 "FDIS" 0 "DIS" ;
VAL_ 2358181630 SCMState 2 "Initialization" 1 "Active" 0 "Inactive" ;
VAL_ 2358181630 ActivationResponseError 255 "GeneralError" 14 "SCVersionNotSupportedBySCM" 13 "SCDConfigLabelLengthIncorrect" 12 "SCDVersionLabelLengthIncorrect" 11 "InvalidGraphicObject" 10 "DesignatorStringthLengthIsZero" 9 "StateIDIsNotUnique" 8 "FunctionIDIsNotUnique" 7 "ObjectIDIsNotUnique" 6 "ReferencedGraphObjDoesNotExist" 5 "ReferencedStringObjDoesNotExist" 4 "ReferencedStateObjDoesNotExist" 3 "ReferencedFunctObjDoesNotExist" 2 "BasicObjectDoesNotExist" 1 "UnknownObjectType" 0 "NoError" ;
VAL_ 2358181630 TransferResponseError 255 "GeneralError" 1 "ErrorOccurredDuringTransfer" 0 "NoError" ;
VAL_ 2358181630 ConfigLabelResponseError 255 "GeneralError" 1 "NoMatchingSCDStored" 0 "NoError" ;
VAL_ 2358181630 VersionResponseError 255 "GeneralError" 1 "NoMatchingSCDStored" 0 "NoError" ;
VAL_ 2358181630 MemoryStatus 0 "EnoughMemoryMayBeAvailable" 1 "NotEnoughMemoryAvailable" ;
VAL_ 2358181630 SequenceNumber 255 "NoSequenceAvailable" ;
VAL_ 2358181630 FunctionExecutionStateAck 3 "AckErrorDuringExecution" 2 "AckOfFunctionExecutionCompleted" 1 "AckOfFunctionExecutionStarted" 0 "AckOfFuncExecStartAndCompletion" ;
VAL_ 2358181630 FunctionExecutionState 3 "ErrorDuringExecution" 2 "FunctionExecutionCompleted" 1 "FunctionExecutionStarted" 0 "FunctionExecStartedAndCompleted" ;
VAL_ 2358181630 ReasonIndicator 255 "NoSpecificReason" 3 "SCCIsPartOfSelectedSCS" 2 "SCCNotPartOfSelectedSCS" 1 "StatusChangeOnOperatorCommand" ;
VAL_ 2358181630 SequenceState 255 "SequenceStateNotAvailable" 5 "Abort" 4 "PlayBack" 3 "RecordingCompletition" 2 "Recording" 1 "Ready" ;
VAL_ 2358181630 ExecutionIndicationResponseError 255 "GeneralError" 6 "PlayBackHaltedDueToOperator" 5 "PlayBackContinues" 4 "SCMOutOfMemory" 3 "FunctionExecutionStateMismatch" 2 "StateIDNotDefined" 1 "FunctionIDNotDefined" 0 "NoError" ;
VAL_ 2358181630 BusyFlagMemoryAccess 1 "BusyWithNonVolatileMemoryAccess" 0 "NotBusy" ;
VAL_ 2358181630 BusyFlagParsing 1 "SCMIsParsingAnSCD" 0 "NotBusy" ;
VAL_ 2358116094 MessageCode 149 "SCMasterStatus" 145 "SCMasterMemoryResponse" 144 "SCMasterCapablilityResponse" 53 "SCClientFunctionErrorRequest" 52 "SCClientExecutionAcknowledgement" 51 "SCMasterExecutionCommand" 50 "SCExecutionIndicationResponse" 48 "SCStateCommand" 7 "SCDLoadResponse" 6 "SCDStoreResponse" 5 "SCDDeleteResponse" 4 "SCDActivationResponse" 3 "SCDTransferResponse" 2 "SCDConfigurationLabelResponse" 1 "SCDVersionResponse" ;
VAL_ 2358116094 DeleteCommandType 1 "DeleteSCDInNonVolatileMemory" 0 "DeleteSCDInVolatileMemory" ;
VAL_ 2358116094 SCCState 2 "Initialization" 1 "Enabled" 0 "Disabled" ;
VAL_ 2358116094 SequenceNumber 255 "NoSequenceAvailable" ;
VAL_ 2358116094 NewFunctionExecutionState 3 "ErrorDuringExecution" 2 "FunctionExecutionCompleted" 1 "FunctionExecutionStarted" 0 "FunctionExecStartedAndCompleted" ;
VAL_ 2358116094 FunctionExecutionState 3 "ErrorDuringExecution" 2 "FunctionExecutionCompleted" 1 "FunctionExecutionStarted" 0 "FunctionExecStartedAndCompleted" ;
VAL_ 2358116094 SequenceState 255 "SequenceStateNotAvailable" 5 "Abort" 4 "PlayBack" 3 "RecordingCompletition" 2 "Recording" 1 "Ready" ;
VAL_ 2358116094 ClientAbortError 255 "GeneralError" 3 "ErrorDuringFunctionExecution" 2 "OperatorInteraction" 1 "TimeoutOnStatusMessage" ;
VAL_ 2358116094 ClientFunctionErrorStatuts1 15 "GeneralError" 4 "ClientFunctionIsDeactivated" 3 "ClientFunctionIsLocked" 2 "PermanentError" 1 "OneTimeError" ;
VAL_ 2358116094 ClientExecutionError 255 "GeneralError" 3 "ConditionsOfSCCAllowNoExecution" 2 "OperatorInteraction" 1 "ErrorInTheFunction" 0 "NoError" ;
VAL_ 2358116094 OperatorConfirmationRequired1 1 "yes" 0 "no" ;
VAL_ 2358116094 ClientFunctonErrorState 255 "ErrorStateNotAvailable" 3 "ErrorStateReqConfirmationChanged" 2 "ErrorStateChanged" 1 "ErrorStateNotChanged" 0 "NoError" ;
VAL_ 2358116094 ClientFunctionErrorStatuts2 15 "GeneralError" 4 "ClientFunctionIsDeactivated" 3 "ClientFunctionIsLocked" 2 "PermanentError" 1 "OneTimeError" ;
VAL_ 2358116094 OperatorConfirmationRequired2 1 "yes" 0 "no" ;
VAL_ 2358116094 ClientFunctionErrorStatuts3 15 "GeneralError" 4 "ClientFunctionIsDeactivated" 3 "ClientFunctionIsLocked" 2 "PermanentError" 1 "OneTimeError" ;
VAL_ 2358116094 OperatorConfirmationRequired3 1 "yes" 0 "no" ;
VAL_ 2365458686 SpeedInfo_EngineSpeed 0 "EngineSpeedInfoNotAvailable" 1 "EngineSpeedInfoAvailable" ;
VAL_ 2365458686 SpeedInfo_GroundBasedSpeed 0 "GndBasedSpeedInfoNotAvailable" 1 "GndBasedSpeedInfoAvailable" ;
VAL_ 2365458686 SpeedInfo_WheelBasedSpeed 0 "WheelBasedSpeedInfoNotAvailable" 1 "WheelBasedSpeedInfoAvailable" ;
VAL_ 2365458686 PowerMgt_MaintainPower 0 "MainPwrMgtNotAvailable" 1 "MainPwrMgtAvailable" ;
VAL_ 2365458686 PowerMgt_MaxTimeTractorPower 0 "MaxTimeTractorPwrMgtNotAvailable" 1 "MaxTimeTractorPwrMgtAvailable" ;
VAL_ 2365458686 PowerMgt_KeySwitch 0 "KeySwitchPwrMgtNotAvailable" 1 "KeySwitchPwrMgtAvailable" ;
VAL_ 2365458686 TractorClass 0 "TECU_Class_1" 1 "TECU_Class_2" 2 "TECU_Class_3" 3 "NotAvailable" ;
VAL_ 2365458686 LanguageCmdStorageInTractorECU 0 "LangCmdNotAvailableInTractorECU" 1 "LangCmdAvailableInTractorECU" ;
VAL_ 2365458686 Lighting_MinimalSet 0 "MinSetNotAvailable" 1 "MinSetAvailable" ;
VAL_ 2365458686 PTOInfo_RearShaftEngagement 0 "PTOInfo_RearShaftEgtNotAvailable" 1 "PTOInfo_RearShaftEgtAvailable" ;
VAL_ 2365458686 PTOInfo_RearShaftSpeed 0 "PTOInfo_RearShaftSpdNotAvailable" 1 "PTOInfo_RearShaftSpdAvailable" ;
VAL_ 2365458686 HitchInfo_RearInWork 0 "HitchInfo_RearInWorkNotAvailable" 1 "HitchInfo_RearInWorkAvailable" ;
VAL_ 2365458686 HitchInfo_RearPosition 0 "HitchInfo_RearInPosNotAvailable" 1 "HitchInfo_RearInPosAvailable" ;
VAL_ 2365458686 EstimatedOrMeasuredAuxValveState 0 "EstOrMeasAuxValStatNotAvailable" 1 "EstOrMeasAuxValStatAvailable" ;
VAL_ 2365458686 Light_FullImplLightingMessageSet 0 "FullImplLightMsgSetNotAvailable" 1 "FullImplLightMsgSetAvailable" ;
VAL_ 2365458686 AddHitchParameter_RearDraft 0 "HitchInfo_RearDraftNotAvailable" 1 "HitchInfo_RearDraftAvailable" ;
VAL_ 2365458686 SpeedAndDist_WheelBasedDirection 0 "WheelBasedDirectionNotAvailable" 1 "WheelBasedDirectionAvailable" ;
VAL_ 2365458686 SpeedAndDist_WheelBasedDistance 0 "WheelBasedDistanceNotAvailable" 1 "WheelBasedDistanceAvailable" ;
VAL_ 2365458686 SpeedAndDist_GndBasedDirection 0 "GndBasedDirectionNotAvailable" 1 "GndBasedDirectionAvailable" ;
VAL_ 2365458686 SpeedAndDist_GndBasedDistance 0 "GndBasedDistanceNotAvailable" 1 "GndBasedDistanceAvailable" ;
VAL_ 2365458686 TimeDate 0 "TimeAndDateNotAvailable" 1 "TimeAndDateAvailable" ;
VAL_ 2365458686 LimitStatusReporting 1 "Facility available" 0 "Facility not available" ;
VAL_ 2365458686 AuxiliaryValveCmd 0 "AuxiliaryValveCmdsNotAvailable" 1 "AuxiliaryValveCmdsAvailable" ;
VAL_ 2365458686 PTOCmd_RearPTOEngagementCmd 0 "RearPTOEgtCmdNotAvailable" 1 "RearPTOEgtCmdAvailable" ;
VAL_ 2365458686 PTOCmd_RearPTOSpeedCmd 0 "RearPTOSpeedCmdNotAvailable" 1 "RearPTOSpeedCmdAvailable" ;
VAL_ 2365458686 HitchCmd_RearHitchPosition 0 "HitchRearPosNotAvailable" 1 "HitchRearPosAvailable" ;
VAL_ 2365458686 NavigPseudorangeNoiseStatistic 0 "NavigPsdoNoiseStatNotAvailable" 1 "NavigPsdoNoiseStatAvailable" ;
VAL_ 2365458686 NavigSystemPositionData 0 "NavigSysPosDataNotAvailable" 1 "NavigSysPosDataAvailable" ;
VAL_ 2365458686 NavigSystemHighOutputPosition 0 "NavigSysHOutPosDataNotAvailable" 1 "NavigSysHOutPosDataAvailable" ;
VAL_ 2365458686 PTOCmd_FrontPTOEngagementCmd 0 "FrontPTOEgtCmdNotAvailable" 1 "FrontPTOEgtCmdAvailable" ;
VAL_ 2365458686 PTOCmd_FrontPTOSpeedCmd 0 "FrontPTOSpeedCmdNotAvailable" 1 "FrontPTOSpeedCmdAvailable" ;
VAL_ 2365458686 HitchCmd_FrontHitchPosition 0 "FrontHitchPosNotAvailable" 1 "FrontHitchPosAvailable" ;
VAL_ 2365458686 AddHitchParameter__FrontDraft 0 "FrontDraftNotAvailable" 1 "FrontDraftAvailable" ;
VAL_ 2365458686 PTOInfo_FrontShaftEngagement 0 "FrontShaftEgtNotAvailable" 1 "FrontShaftEgtAvailable" ;
VAL_ 2365458686 PTOInfo_FrontShaftSpeed 0 "FrontShaftSpeedNotAvailable" 1 "FrontShaftSpeedAvailable" ;
VAL_ 2365458686 HitchInfo_FrontInWork 0 "FrontInWorkNotAvailable" 1 "FrontInWorkAvailable" ;
VAL_ 2365458686 HitchInfo_FrontPosition 0 "FrontPositionNotAvailable" 1 "FrontPositionAvailable" ;
VAL_ 2365473790 RearPTOEngagementRqStatus 3 "Not available" 2 "Error" 1 "Control Override" 0 "External Request accepted" ;
VAL_ 2365473790 RearPTOEconomyMode 0 "PTOEconomyModeIsDisengaged" 1 "PTOEconomyModeIsEngaged" 2 "ErrorIndication" 3 "NotAvailabel" ;
VAL_ 2365473790 RearPTOMode 0 "PTOModeIs540" 1 "PTOModeIs1000" 2 "ErrorIndication" 3 "NotAvailable" ;
VAL_ 2365473790 RearPTOEngagement 0 "PTODisengaged" 1 "PTOEngaged" 2 "ErrorIndication" 3 "NotAvailable" ;
VAL_ 2365473790 RearPTOShaftSpeedLimitStatus 7 "Not available" 6 "Non-recoverable Fault" 5 "Reserver" 4 "Reserved" 3 "Limited Low" 2 "Limited High" 1 "Operator Limited" 0 "Not limited" ;
VAL_ 2365473790 RearPTOEconomyModeRqStatus 3 "Not available" 2 "Error" 1 "Control Override" 0 "External Request accepted" ;
VAL_ 2365473790 RearPTOModeRqStatus 3 "Not available" 2 "Error" 1 "Control Override" 0 "External Request accepted" ;
VAL_ 2365474302 RearHitchPositionLimitStatus 7 "Not available" 6 "Non-recoverable Fault" 5 "Reserver" 4 "Reserved" 3 "Limited Low" 2 "Limited High" 1 "Operator Limited" 0 "Not limited" ;
VAL_ 2365474302 RearHitchInWorkIndication 0 "HitchPositionIsOutOfWork" 1 "HitchPositionIsInWork" 2 "ErrorIndication" 3 "NotAvailable" ;
SG_MUL_VAL_ 2632384254 NrOfVersionStrings VTFunctionVTtoECU 224-224, 211-211;
SG_MUL_VAL_ 2632384254 ErrorCodeExecuteOpCode1 VTFunctionVTtoECU 11-11, 191-191;
SG_MUL_VAL_ 2632384254 ErrorCodeExecuteOpCode2 VTFunctionVTtoECU 11-11, 191-191;
SG_MUL_VAL_ 2632384254 ErrorCodeExecuteOpCode3 VTFunctionVTtoECU 11-11, 191-191;
SG_MUL_VAL_ 2632384254 ErrorCodeExecuteOpCode4 VTFunctionVTtoECU 11-11, 191-191;
SG_MUL_VAL_ 2632384254 ErrorCodeExecuteOpCode5 VTFunctionVTtoECU 11-11, 191-191;
SG_MUL_VAL_ 2632384254 ErrorCodeExecuteOpCode6 VTFunctionVTtoECU 11-11, 191-191;
SG_MUL_VAL_ 2632384254 ErrorCodeExecuteOpCode7 VTFunctionVTtoECU 11-11, 191-191;
SG_MUL_VAL_ 2632384254 AcknowledgmentStoreVersion VTFunctionVTtoECU 208-208, 212-212;
SG_MUL_VAL_ 2632384254 AcknowledgmentLoadVersion VTFunctionVTtoECU 209-209, 213-213;
SG_MUL_VAL_ 2632384254 AcknowledgmentDeleteVersion VTFunctionVTtoECU 210-210, 214-214;
SG_MUL_VAL_ 2358181630 LoadResponseError MessageCode 7-7;
SG_MUL_VAL_ 2358181630 StoreCommandError MessageCode 6-6;
SG_MUL_VAL_ 2358181630 DeleteCommandResponseError MessageCode 5-5;
SG_MUL_VAL_ 2358181630 CommandedSCCState MessageCode 48-48;
SG_MUL_VAL_ 2358181630 SCVersion MessageCode 144-144;
SG_MUL_VAL_ 2358181630 FunctionID MessageCode 50-50;
SG_MUL_VAL_ 2358181630 SCMState MessageCode 149-149;
SG_MUL_VAL_ 2358181630 ActivationResponseError MessageCode 4-4;
SG_MUL_VAL_ 2358181630 TransferResponseError MessageCode 3-3;
SG_MUL_VAL_ 2358181630 ConfigLabelResponseError MessageCode 2-2;
SG_MUL_VAL_ 2358181630 VersionResponseError MessageCode 1-1;
SG_MUL_VAL_ 2358181630 MemoryStatus MessageCode 145-145;
SG_MUL_VAL_ 2358181630 RecordedFunctionID MessageCode 51-51, 52-52;
SG_MUL_VAL_ 2358181630 ObjectIdOfFirstFaultyObject MessageCode 4-4;
SG_MUL_VAL_ 2358181630 SequenceNumber MessageCode 149-149;
SG_MUL_VAL_ 2358181630 RecordedStateID MessageCode 51-51;
SG_MUL_VAL_ 2358181630 GraphicsWidth MessageCode 144-144;
SG_MUL_VAL_ 2358181630 ActualVersionLabel VersionResponseError 0-0;
SG_MUL_VAL_ 2358181630 ActualConfigurationLabel ConfigLabelResponseError 0-0;
SG_MUL_VAL_ 2358181630 StateID MessageCode 50-50, 52-52;
SG_MUL_VAL_ 2358181630 FunctionExecutionStateAck MessageCode 52-52;
SG_MUL_VAL_ 2358181630 FunctionExecutionState MessageCode 50-50;
SG_MUL_VAL_ 2358181630 GraphicsHeight MessageCode 144-144;
SG_MUL_VAL_ 2358181630 ReasonIndicator MessageCode 48-48;
SG_MUL_VAL_ 2358181630 SequenceState MessageCode 149-149;
SG_MUL_VAL_ 2358181630 TAN MessageCode 51-51, 52-52;
SG_MUL_VAL_ 2358181630 ExecutionIndicationResponseError MessageCode 50-50;
SG_MUL_VAL_ 2358181630 BusyFlagMemoryAccess MessageCode 149-149;
SG_MUL_VAL_ 2358181630 RecordedFunctionValue MessageCode 51-51;
SG_MUL_VAL_ 2358181630 ReceivedTAN MessageCode 50-50;
SG_MUL_VAL_ 2358181630 BusyFlagParsing MessageCode 149-149;
SG_MUL_VAL_ 2358181630 MaxDesignatorStringLength MessageCode 144-144;
SG_MUL_VAL_ 2358116094 DeleteCommandType MessageCode 5-5;
SG_MUL_VAL_ 2358116094 AddressSCCWSM MessageCode 4-4;
SG_MUL_VAL_ 2358116094 MemoryRequired MessageCode 145-145;
SG_MUL_VAL_ 2358116094 FunctionID MessageCode 50-50;
SG_MUL_VAL_ 2358116094 SCCState MessageCode 150-150;
SG_MUL_VAL_ 2358116094 RecordedFunctionID MessageCode 52-52;
SG_MUL_VAL_ 2358116094 NumberOfFaultyFunctions MessageCode 53-53;
SG_MUL_VAL_ 2358116094 SequenceNumber MessageCode 150-150;
SG_MUL_VAL_ 2358116094 StateID MessageCode 50-50;
SG_MUL_VAL_ 2358116094 IDOfFaultyClientFunction1 NumberOfFaultyFunctions 1-255;
SG_MUL_VAL_ 2358116094 NewStateID MessageCode 52-52;
SG_MUL_VAL_ 2358116094 NewFunctionExecutionState MessageCode 52-52;
SG_MUL_VAL_ 2358116094 FunctionExecutionState MessageCode 50-50;
SG_MUL_VAL_ 2358116094 SequenceState MessageCode 150-150;
SG_MUL_VAL_ 2358116094 ClientAbortError MessageCode 49-49;
SG_MUL_VAL_ 2358116094 ClientFunctionErrorStatuts1 NumberOfFaultyFunctions 1-255;
SG_MUL_VAL_ 2358116094 ClientExecutionError MessageCode 52-52;
SG_MUL_VAL_ 2358116094 TAN MessageCode 50-50;
SG_MUL_VAL_ 2358116094 OperatorConfirmationRequired1 NumberOfFaultyFunctions 1-255;
SG_MUL_VAL_ 2358116094 ClientFunctonErrorState MessageCode 150-150;
SG_MUL_VAL_ 2358116094 IDOfFaultyClientFunction2 NumberOfFaultyFunctions 2-255;
SG_MUL_VAL_ 2358116094 FunctionValue FunctionExecutionState 0-0, 2-2;
SG_MUL_VAL_ 2358116094 ReceivedTAN MessageCode 52-52;
SG_MUL_VAL_ 2358116094 ClientFunctionErrorStatuts2 NumberOfFaultyFunctions 2-255;
SG_MUL_VAL_ 2358116094 OperatorConfirmationRequired2 NumberOfFaultyFunctions 2-255;
SG_MUL_VAL_ 2358116094 IDOfFaultyClientFunction3 NumberOfFaultyFunctions 3-255;
SG_MUL_VAL_ 2358116094 ClientFunctionErrorStatuts3 NumberOfFaultyFunctions 3-255;
SG_MUL_VAL_ 2358116094 OperatorConfirmationRequired3 NumberOfFaultyFunctions 3-255;
